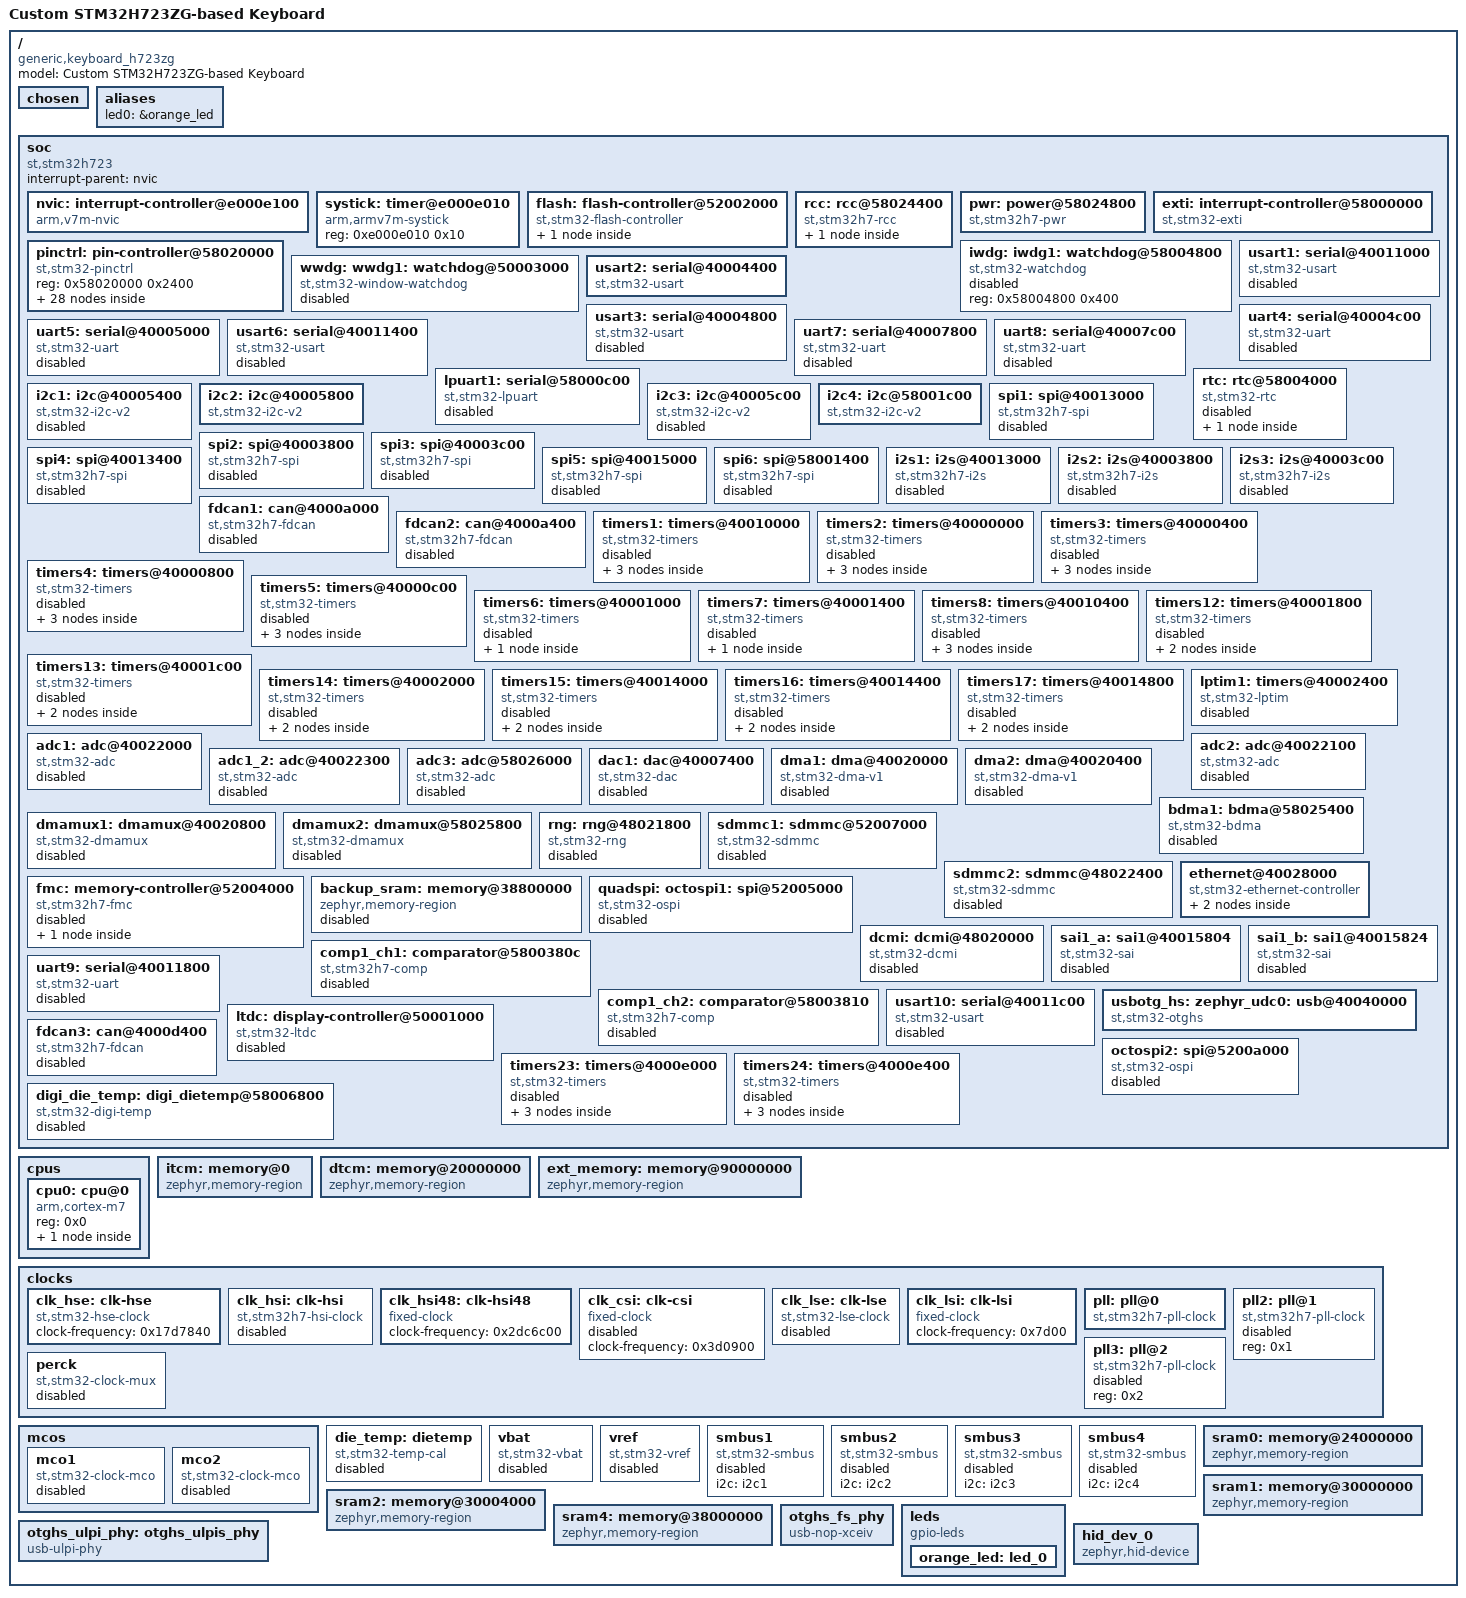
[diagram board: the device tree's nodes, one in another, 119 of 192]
/dts-v1/;

/* node '/' defined in zephyr/dts/common/skeleton.dtsi:9 */
/ {
	#address-cells = < 0x1 >;                    /* in zephyr/dts/common/skeleton.dtsi:10 */
	#size-cells = < 0x1 >;                       /* in zephyr/dts/common/skeleton.dtsi:11 */
	model = "Custom STM32H723ZG-based Keyboard"; /* in workspace/hid-keyboard/boards/generic/keyboard_h723zg/keyboard_h723zg.dts:12 */
	compatible = "generic,keyboard_h723zg";      /* in workspace/hid-keyboard/boards/generic/keyboard_h723zg/keyboard_h723zg.dts:13 */

	/* node '/chosen' defined in zephyr/dts/common/skeleton.dtsi:13 */
	chosen {
		zephyr,entropy = &rng;            /* in zephyr/dts/arm/st/h7/stm32h7.dtsi:29 */
		zephyr,flash-controller = &flash; /* in zephyr/dts/arm/st/h7/stm32h7.dtsi:30 */
		zephyr,console = &usart2;         /* in workspace/hid-keyboard/boards/generic/keyboard_h723zg/keyboard_h723zg.dts:16 */
		zephyr,shell-uart = &usart2;      /* in workspace/hid-keyboard/boards/generic/keyboard_h723zg/keyboard_h723zg.dts:17 */
		zephyr,sram = &sram0;             /* in workspace/hid-keyboard/boards/generic/keyboard_h723zg/keyboard_h723zg.dts:18 */
		zephyr,flash = &flash0;           /* in workspace/hid-keyboard/boards/generic/keyboard_h723zg/keyboard_h723zg.dts:19 */
		zephyr,dtcm = &dtcm;              /* in workspace/hid-keyboard/boards/generic/keyboard_h723zg/keyboard_h723zg.dts:20 */
	};

	/* node '/aliases' defined in zephyr/dts/common/skeleton.dtsi:15 */
	aliases {
		led0 = &orange_led; /* in workspace/hid-keyboard/boards/generic/keyboard_h723zg/keyboard_h723zg.dts:38 */
	};

	/* node '/soc' defined in zephyr/dts/arm/armv7-m.dtsi:6 */
	soc {
		#address-cells = < 0x1 >;     /* in zephyr/dts/arm/armv7-m.dtsi:7 */
		#size-cells = < 0x1 >;        /* in zephyr/dts/arm/armv7-m.dtsi:8 */
		interrupt-parent = < &nvic >; /* in zephyr/dts/arm/armv7-m.dtsi:10 */
		ranges;                       /* in zephyr/dts/arm/armv7-m.dtsi:11 */
		compatible = "st,stm32h723",
		             "st,stm32h7",
		             "simple-bus";    /* in zephyr/dts/arm/st/h7/stm32h723.dtsi:15 */

		/* node '/soc/interrupt-controller@e000e100' defined in zephyr/dts/arm/armv7-m.dtsi:13 */
		nvic: interrupt-controller@e000e100 {
			#address-cells = < 0x1 >;            /* in zephyr/dts/arm/armv7-m.dtsi:14 */
			compatible = "arm,v7m-nvic";         /* in zephyr/dts/arm/armv7-m.dtsi:15 */
			reg = < 0xe000e100 0xc00 >;          /* in zephyr/dts/arm/armv7-m.dtsi:16 */
			interrupt-controller;                /* in zephyr/dts/arm/armv7-m.dtsi:17 */
			#interrupt-cells = < 0x2 >;          /* in zephyr/dts/arm/armv7-m.dtsi:18 */
			arm,num-irq-priority-bits = < 0x4 >; /* in zephyr/dts/arm/st/h7/stm32h7.dtsi:1293 */
			phandle = < 0x1 >;                   /* in zephyr/dts/arm/armv7-m.dtsi:10 */
		};

		/* node '/soc/timer@e000e010' defined in zephyr/dts/arm/armv7-m.dtsi:21 */
		systick: timer@e000e010 {
			compatible = "arm,armv7m-systick"; /* in zephyr/dts/arm/armv7-m.dtsi:22 */
			reg = < 0xe000e010 0x10 >;         /* in zephyr/dts/arm/armv7-m.dtsi:23 */
		};

		/* node '/soc/flash-controller@52002000' defined in zephyr/dts/arm/st/h7/stm32h7.dtsi:158 */
		flash: flash-controller@52002000 {
			compatible = "st,stm32-flash-controller",
			             "st,stm32h7-flash-controller"; /* in zephyr/dts/arm/st/h7/stm32h7.dtsi:159 */
			reg = < 0x52002000 0x400 >;                 /* in zephyr/dts/arm/st/h7/stm32h7.dtsi:160 */
			interrupts = < 0x4 0x0 >;                   /* in zephyr/dts/arm/st/h7/stm32h7.dtsi:161 */
			#address-cells = < 0x1 >;                   /* in zephyr/dts/arm/st/h7/stm32h7.dtsi:163 */
			#size-cells = < 0x1 >;                      /* in zephyr/dts/arm/st/h7/stm32h7.dtsi:164 */

			/* node '/soc/flash-controller@52002000/flash@8000000' defined in zephyr/dts/arm/st/h7/stm32h723.dtsi:18 */
			flash0: flash@8000000 {
				compatible = "st,stm32-nv-flash",
				             "soc-nv-flash";      /* in zephyr/dts/arm/st/h7/stm32h723.dtsi:19 */
				write-block-size = < 0x20 >;      /* in zephyr/dts/arm/st/h7/stm32h723.dtsi:20 */
				erase-block-size = < 0x20000 >;   /* in zephyr/dts/arm/st/h7/stm32h723.dtsi:21 */
				max-erase-time = < 0xfa0 >;       /* in zephyr/dts/arm/st/h7/stm32h723.dtsi:23 */
				reg = < 0x8000000 0x100000 >;     /* in zephyr/dts/arm/st/h7/stm32h723Xg.dtsi:13 */
			};
		};

		/* node '/soc/rcc@58024400' defined in zephyr/dts/arm/st/h7/stm32h7.dtsi:167 */
		rcc: rcc@58024400 {
			compatible = "st,stm32h7-rcc";    /* in zephyr/dts/arm/st/h7/stm32h7.dtsi:168 */
			#clock-cells = < 0x2 >;           /* in zephyr/dts/arm/st/h7/stm32h7.dtsi:169 */
			reg = < 0x58024400 0x400 >;       /* in zephyr/dts/arm/st/h7/stm32h7.dtsi:170 */
			clocks = < &pll >;                /* in workspace/hid-keyboard/boards/generic/keyboard_h723zg/keyboard_h723zg.dts:66 */
			clock-frequency = < 0x20c85580 >; /* in workspace/hid-keyboard/boards/generic/keyboard_h723zg/keyboard_h723zg.dts:67 */
			d1cpre = < 0x1 >;                 /* in workspace/hid-keyboard/boards/generic/keyboard_h723zg/keyboard_h723zg.dts:68 */
			hpre = < 0x2 >;                   /* in workspace/hid-keyboard/boards/generic/keyboard_h723zg/keyboard_h723zg.dts:69 */
			d1ppre = < 0x2 >;                 /* in workspace/hid-keyboard/boards/generic/keyboard_h723zg/keyboard_h723zg.dts:70 */
			d2ppre1 = < 0x2 >;                /* in workspace/hid-keyboard/boards/generic/keyboard_h723zg/keyboard_h723zg.dts:71 */
			d2ppre2 = < 0x2 >;                /* in workspace/hid-keyboard/boards/generic/keyboard_h723zg/keyboard_h723zg.dts:72 */
			d3ppre = < 0x2 >;                 /* in workspace/hid-keyboard/boards/generic/keyboard_h723zg/keyboard_h723zg.dts:73 */
			phandle = < 0x3 >;                /* in zephyr/dts/arm/st/h7/stm32h7.dtsi:193 */

			/* node '/soc/rcc@58024400/reset-controller' defined in zephyr/dts/arm/st/h7/stm32h7.dtsi:172 */
			rctl: reset-controller {
				compatible = "st,stm32-rcc-rctl"; /* in zephyr/dts/arm/st/h7/stm32h7.dtsi:173 */
				#reset-cells = < 0x1 >;           /* in zephyr/dts/arm/st/h7/stm32h7.dtsi:174 */
				phandle = < 0x4 >;                /* in zephyr/dts/arm/st/h7/stm32h7.dtsi:316 */
			};
		};

		/* node '/soc/power@58024800' defined in zephyr/dts/arm/st/h7/stm32h7.dtsi:178 */
		pwr: power@58024800 {
			compatible = "st,stm32h7-pwr"; /* in zephyr/dts/arm/st/h7/stm32h7.dtsi:183 */
			reg = < 0x58024800 0x400 >;    /* in zephyr/dts/arm/st/h7/stm32h7.dtsi:184 */
			power-supply = "ldo";          /* in workspace/hid-keyboard/boards/generic/keyboard_h723zg/keyboard_h723zg.dts:77 */
		};

		/* node '/soc/interrupt-controller@58000000' defined in zephyr/dts/arm/st/h7/stm32h7.dtsi:187 */
		exti: interrupt-controller@58000000 {
			compatible = "st,stm32-exti";  /* in zephyr/dts/arm/st/h7/stm32h7.dtsi:188 */
			interrupt-controller;          /* in zephyr/dts/arm/st/h7/stm32h7.dtsi:189 */
			#interrupt-cells = < 0x1 >;    /* in zephyr/dts/arm/st/h7/stm32h7.dtsi:190 */
			#address-cells = < 0x0 >;      /* in zephyr/dts/arm/st/h7/stm32h7.dtsi:191 */
			reg = < 0x58000000 0x400 >;    /* in zephyr/dts/arm/st/h7/stm32h7.dtsi:192 */
			clocks = < &rcc 0xf4 0x2 >;    /* in zephyr/dts/arm/st/h7/stm32h7.dtsi:193 */
			num-lines = < 0x60 >;          /* in zephyr/dts/arm/st/h7/stm32h7.dtsi:194 */
			interrupts = < 0x6 0x0 >,
			             < 0x7 0x0 >,
			             < 0x8 0x0 >,
			             < 0x9 0x0 >,
			             < 0xa 0x0 >,
			             < 0x17 0x0 >,
			             < 0x28 0x0 >;     /* in zephyr/dts/arm/st/h7/stm32h7.dtsi:195 */
			interrupt-names = "line0",
			                  "line1",
			                  "line2",
			                  "line3",
			                  "line4",
			                  "line5-9",
			                  "line10-15"; /* in zephyr/dts/arm/st/h7/stm32h7.dtsi:197 */
			line-ranges = < 0x0 0x1 >,
			              < 0x1 0x1 >,
			              < 0x2 0x1 >,
			              < 0x3 0x1 >,
			              < 0x4 0x1 >,
			              < 0x5 0x5 >,
			              < 0xa 0x6 >;     /* in zephyr/dts/arm/st/h7/stm32h7.dtsi:199 */
		};

		/* node '/soc/pin-controller@58020000' defined in zephyr/dts/arm/st/h7/stm32h7.dtsi:203 */
		pinctrl: pin-controller@58020000 {
			compatible = "st,stm32-pinctrl"; /* in zephyr/dts/arm/st/h7/stm32h7.dtsi:204 */
			#address-cells = < 0x1 >;        /* in zephyr/dts/arm/st/h7/stm32h7.dtsi:205 */
			#size-cells = < 0x1 >;           /* in zephyr/dts/arm/st/h7/stm32h7.dtsi:206 */
			reg = < 0x58020000 0x2400 >;     /* in zephyr/dts/arm/st/h7/stm32h7.dtsi:207 */

			/* node '/soc/pin-controller@58020000/gpio@58020000' defined in zephyr/dts/arm/st/h7/stm32h7.dtsi:209 */
			gpioa: gpio@58020000 {
				compatible = "st,stm32-gpio"; /* in zephyr/dts/arm/st/h7/stm32h7.dtsi:210 */
				gpio-controller;              /* in zephyr/dts/arm/st/h7/stm32h7.dtsi:211 */
				#gpio-cells = < 0x2 >;        /* in zephyr/dts/arm/st/h7/stm32h7.dtsi:212 */
				reg = < 0x58020000 0x400 >;   /* in zephyr/dts/arm/st/h7/stm32h7.dtsi:213 */
				clocks = < &rcc 0xe0 0x1 >;   /* in zephyr/dts/arm/st/h7/stm32h7.dtsi:214 */
			};

			/* node '/soc/pin-controller@58020000/gpio@58020400' defined in zephyr/dts/arm/st/h7/stm32h7.dtsi:217 */
			gpiob: gpio@58020400 {
				compatible = "st,stm32-gpio"; /* in zephyr/dts/arm/st/h7/stm32h7.dtsi:218 */
				gpio-controller;              /* in zephyr/dts/arm/st/h7/stm32h7.dtsi:219 */
				#gpio-cells = < 0x2 >;        /* in zephyr/dts/arm/st/h7/stm32h7.dtsi:220 */
				reg = < 0x58020400 0x400 >;   /* in zephyr/dts/arm/st/h7/stm32h7.dtsi:221 */
				clocks = < &rcc 0xe0 0x2 >;   /* in zephyr/dts/arm/st/h7/stm32h7.dtsi:222 */
			};

			/* node '/soc/pin-controller@58020000/gpio@58020800' defined in zephyr/dts/arm/st/h7/stm32h7.dtsi:225 */
			gpioc: gpio@58020800 {
				compatible = "st,stm32-gpio"; /* in zephyr/dts/arm/st/h7/stm32h7.dtsi:226 */
				gpio-controller;              /* in zephyr/dts/arm/st/h7/stm32h7.dtsi:227 */
				#gpio-cells = < 0x2 >;        /* in zephyr/dts/arm/st/h7/stm32h7.dtsi:228 */
				reg = < 0x58020800 0x400 >;   /* in zephyr/dts/arm/st/h7/stm32h7.dtsi:229 */
				clocks = < &rcc 0xe0 0x4 >;   /* in zephyr/dts/arm/st/h7/stm32h7.dtsi:230 */
			};

			/* node '/soc/pin-controller@58020000/gpio@58020c00' defined in zephyr/dts/arm/st/h7/stm32h7.dtsi:233 */
			gpiod: gpio@58020c00 {
				compatible = "st,stm32-gpio"; /* in zephyr/dts/arm/st/h7/stm32h7.dtsi:234 */
				gpio-controller;              /* in zephyr/dts/arm/st/h7/stm32h7.dtsi:235 */
				#gpio-cells = < 0x2 >;        /* in zephyr/dts/arm/st/h7/stm32h7.dtsi:236 */
				reg = < 0x58020c00 0x400 >;   /* in zephyr/dts/arm/st/h7/stm32h7.dtsi:237 */
				clocks = < &rcc 0xe0 0x8 >;   /* in zephyr/dts/arm/st/h7/stm32h7.dtsi:238 */
				phandle = < 0x20 >;           /* in workspace/hid-keyboard/boards/generic/keyboard_h723zg/keyboard_h723zg.dts:27 */
			};

			/* node '/soc/pin-controller@58020000/gpio@58021000' defined in zephyr/dts/arm/st/h7/stm32h7.dtsi:241 */
			gpioe: gpio@58021000 {
				compatible = "st,stm32-gpio"; /* in zephyr/dts/arm/st/h7/stm32h7.dtsi:242 */
				gpio-controller;              /* in zephyr/dts/arm/st/h7/stm32h7.dtsi:243 */
				#gpio-cells = < 0x2 >;        /* in zephyr/dts/arm/st/h7/stm32h7.dtsi:244 */
				reg = < 0x58021000 0x400 >;   /* in zephyr/dts/arm/st/h7/stm32h7.dtsi:245 */
				clocks = < &rcc 0xe0 0x10 >;  /* in zephyr/dts/arm/st/h7/stm32h7.dtsi:246 */
			};

			/* node '/soc/pin-controller@58020000/gpio@58021400' defined in zephyr/dts/arm/st/h7/stm32h7.dtsi:249 */
			gpiof: gpio@58021400 {
				compatible = "st,stm32-gpio"; /* in zephyr/dts/arm/st/h7/stm32h7.dtsi:250 */
				gpio-controller;              /* in zephyr/dts/arm/st/h7/stm32h7.dtsi:251 */
				#gpio-cells = < 0x2 >;        /* in zephyr/dts/arm/st/h7/stm32h7.dtsi:252 */
				reg = < 0x58021400 0x400 >;   /* in zephyr/dts/arm/st/h7/stm32h7.dtsi:253 */
				clocks = < &rcc 0xe0 0x20 >;  /* in zephyr/dts/arm/st/h7/stm32h7.dtsi:254 */
			};

			/* node '/soc/pin-controller@58020000/gpio@58021800' defined in zephyr/dts/arm/st/h7/stm32h7.dtsi:257 */
			gpiog: gpio@58021800 {
				compatible = "st,stm32-gpio"; /* in zephyr/dts/arm/st/h7/stm32h7.dtsi:258 */
				gpio-controller;              /* in zephyr/dts/arm/st/h7/stm32h7.dtsi:259 */
				#gpio-cells = < 0x2 >;        /* in zephyr/dts/arm/st/h7/stm32h7.dtsi:260 */
				reg = < 0x58021800 0x400 >;   /* in zephyr/dts/arm/st/h7/stm32h7.dtsi:261 */
				clocks = < &rcc 0xe0 0x40 >;  /* in zephyr/dts/arm/st/h7/stm32h7.dtsi:262 */
			};

			/* node '/soc/pin-controller@58020000/gpio@58021c00' defined in zephyr/dts/arm/st/h7/stm32h7.dtsi:265 */
			gpioh: gpio@58021c00 {
				compatible = "st,stm32-gpio"; /* in zephyr/dts/arm/st/h7/stm32h7.dtsi:266 */
				gpio-controller;              /* in zephyr/dts/arm/st/h7/stm32h7.dtsi:267 */
				#gpio-cells = < 0x2 >;        /* in zephyr/dts/arm/st/h7/stm32h7.dtsi:268 */
				reg = < 0x58021c00 0x400 >;   /* in zephyr/dts/arm/st/h7/stm32h7.dtsi:269 */
				clocks = < &rcc 0xe0 0x80 >;  /* in zephyr/dts/arm/st/h7/stm32h7.dtsi:270 */
			};

			/* node '/soc/pin-controller@58020000/gpio@58022000' defined in zephyr/dts/arm/st/h7/stm32h7.dtsi:273 */
			gpioi: gpio@58022000 {
				compatible = "st,stm32-gpio"; /* in zephyr/dts/arm/st/h7/stm32h7.dtsi:274 */
				gpio-controller;              /* in zephyr/dts/arm/st/h7/stm32h7.dtsi:275 */
				#gpio-cells = < 0x2 >;        /* in zephyr/dts/arm/st/h7/stm32h7.dtsi:276 */
				reg = < 0x58022000 0x400 >;   /* in zephyr/dts/arm/st/h7/stm32h7.dtsi:277 */
				clocks = < &rcc 0xe0 0x100 >; /* in zephyr/dts/arm/st/h7/stm32h7.dtsi:278 */
			};

			/* node '/soc/pin-controller@58020000/gpio@58022400' defined in zephyr/dts/arm/st/h7/stm32h7.dtsi:281 */
			gpioj: gpio@58022400 {
				compatible = "st,stm32-gpio"; /* in zephyr/dts/arm/st/h7/stm32h7.dtsi:282 */
				gpio-controller;              /* in zephyr/dts/arm/st/h7/stm32h7.dtsi:283 */
				#gpio-cells = < 0x2 >;        /* in zephyr/dts/arm/st/h7/stm32h7.dtsi:284 */
				reg = < 0x58022400 0x400 >;   /* in zephyr/dts/arm/st/h7/stm32h7.dtsi:285 */
				clocks = < &rcc 0xe0 0x200 >; /* in zephyr/dts/arm/st/h7/stm32h7.dtsi:286 */
			};

			/* node '/soc/pin-controller@58020000/gpio@58022800' defined in zephyr/dts/arm/st/h7/stm32h7.dtsi:289 */
			gpiok: gpio@58022800 {
				compatible = "st,stm32-gpio"; /* in zephyr/dts/arm/st/h7/stm32h7.dtsi:290 */
				gpio-controller;              /* in zephyr/dts/arm/st/h7/stm32h7.dtsi:291 */
				#gpio-cells = < 0x2 >;        /* in zephyr/dts/arm/st/h7/stm32h7.dtsi:292 */
				reg = < 0x58022800 0x400 >;   /* in zephyr/dts/arm/st/h7/stm32h7.dtsi:293 */
				clocks = < &rcc 0xe0 0x400 >; /* in zephyr/dts/arm/st/h7/stm32h7.dtsi:294 */
			};

			/* node '/soc/pin-controller@58020000/i2c2_scl_pf1' defined in modules/hal/stm32/dts/st/h7/stm32h723zgtx-pinctrl.dtsi:1919 */
			i2c2_scl_pf1: i2c2_scl_pf1 {
				pinmux = < 0xa24 >; /* in modules/hal/stm32/dts/st/h7/stm32h723zgtx-pinctrl.dtsi:1920 */
				bias-pull-up;       /* in modules/hal/stm32/dts/st/h7/stm32h723zgtx-pinctrl.dtsi:1921 */
				drive-open-drain;   /* in modules/hal/stm32/dts/st/h7/stm32h723zgtx-pinctrl.dtsi:1922 */
				phandle = < 0x6 >;  /* in workspace/hid-keyboard/boards/generic/keyboard_h723zg/keyboard_h723zg.dts:99 */
			};

			/* node '/soc/pin-controller@58020000/i2c4_scl_pf14' defined in modules/hal/stm32/dts/st/h7/stm32h723zgtx-pinctrl.dtsi:1949 */
			i2c4_scl_pf14: i2c4_scl_pf14 {
				pinmux = < 0xbc4 >; /* in modules/hal/stm32/dts/st/h7/stm32h723zgtx-pinctrl.dtsi:1950 */
				bias-pull-up;       /* in modules/hal/stm32/dts/st/h7/stm32h723zgtx-pinctrl.dtsi:1951 */
				drive-open-drain;   /* in modules/hal/stm32/dts/st/h7/stm32h723zgtx-pinctrl.dtsi:1952 */
				phandle = < 0x8 >;  /* in workspace/hid-keyboard/boards/generic/keyboard_h723zg/keyboard_h723zg.dts:92 */
			};

			/* node '/soc/pin-controller@58020000/i2c2_sda_pf0' defined in modules/hal/stm32/dts/st/h7/stm32h723zgtx-pinctrl.dtsi:1993 */
			i2c2_sda_pf0: i2c2_sda_pf0 {
				pinmux = < 0xa04 >; /* in modules/hal/stm32/dts/st/h7/stm32h723zgtx-pinctrl.dtsi:1994 */
				bias-pull-up;       /* in modules/hal/stm32/dts/st/h7/stm32h723zgtx-pinctrl.dtsi:1995 */
				drive-open-drain;   /* in modules/hal/stm32/dts/st/h7/stm32h723zgtx-pinctrl.dtsi:1996 */
				phandle = < 0x7 >;  /* in workspace/hid-keyboard/boards/generic/keyboard_h723zg/keyboard_h723zg.dts:99 */
			};

			/* node '/soc/pin-controller@58020000/i2c4_sda_pf15' defined in modules/hal/stm32/dts/st/h7/stm32h723zgtx-pinctrl.dtsi:2023 */
			i2c4_sda_pf15: i2c4_sda_pf15 {
				pinmux = < 0xbe4 >; /* in modules/hal/stm32/dts/st/h7/stm32h723zgtx-pinctrl.dtsi:2024 */
				bias-pull-up;       /* in modules/hal/stm32/dts/st/h7/stm32h723zgtx-pinctrl.dtsi:2025 */
				drive-open-drain;   /* in modules/hal/stm32/dts/st/h7/stm32h723zgtx-pinctrl.dtsi:2026 */
				phandle = < 0x9 >;  /* in workspace/hid-keyboard/boards/generic/keyboard_h723zg/keyboard_h723zg.dts:92 */
			};

			/* node '/soc/pin-controller@58020000/usart2_tx_pa2' defined in modules/hal/stm32/dts/st/h7/stm32h723zgtx-pinctrl.dtsi:4608 */
			usart2_tx_pa2: usart2_tx_pa2 {
				pinmux = < 0x47 >; /* in modules/hal/stm32/dts/st/h7/stm32h723zgtx-pinctrl.dtsi:4609 */
				bias-pull-up;      /* in modules/hal/stm32/dts/st/h7/stm32h723zgtx-pinctrl.dtsi:4610 */
				phandle = < 0x5 >; /* in workspace/hid-keyboard/boards/generic/keyboard_h723zg/keyboard_h723zg.dts:81 */
			};

			/* node '/soc/pin-controller@58020000/usb_otg_hs_ulpi_d0_pa3' defined in modules/hal/stm32/dts/st/h7/stm32h723zgtx-pinctrl.dtsi:4742 */
			usb_otg_hs_ulpi_d0_pa3: usb_otg_hs_ulpi_d0_pa3 {
				pinmux = < 0x6a >;        /* in modules/hal/stm32/dts/st/h7/stm32h723zgtx-pinctrl.dtsi:4743 */
				slew-rate = "high-speed"; /* in modules/hal/stm32/dts/st/h7/stm32h723zgtx-pinctrl.dtsi:4744 */
				phandle = < 0xe >;        /* in workspace/hid-keyboard/boards/generic/keyboard_h723zg/keyboard_h723zg.dts:107 */
			};

			/* node '/soc/pin-controller@58020000/usb_otg_hs_ulpi_ck_pa5' defined in modules/hal/stm32/dts/st/h7/stm32h723zgtx-pinctrl.dtsi:4747 */
			usb_otg_hs_ulpi_ck_pa5: usb_otg_hs_ulpi_ck_pa5 {
				pinmux = < 0xaa >;        /* in modules/hal/stm32/dts/st/h7/stm32h723zgtx-pinctrl.dtsi:4748 */
				slew-rate = "high-speed"; /* in modules/hal/stm32/dts/st/h7/stm32h723zgtx-pinctrl.dtsi:4749 */
				phandle = < 0xd >;        /* in workspace/hid-keyboard/boards/generic/keyboard_h723zg/keyboard_h723zg.dts:107 */
			};

			/* node '/soc/pin-controller@58020000/usb_otg_hs_ulpi_d1_pb0' defined in modules/hal/stm32/dts/st/h7/stm32h723zgtx-pinctrl.dtsi:4752 */
			usb_otg_hs_ulpi_d1_pb0: usb_otg_hs_ulpi_d1_pb0 {
				pinmux = < 0x20a >;       /* in modules/hal/stm32/dts/st/h7/stm32h723zgtx-pinctrl.dtsi:4753 */
				slew-rate = "high-speed"; /* in modules/hal/stm32/dts/st/h7/stm32h723zgtx-pinctrl.dtsi:4754 */
				phandle = < 0xf >;        /* in workspace/hid-keyboard/boards/generic/keyboard_h723zg/keyboard_h723zg.dts:107 */
			};

			/* node '/soc/pin-controller@58020000/usb_otg_hs_ulpi_d2_pb1' defined in modules/hal/stm32/dts/st/h7/stm32h723zgtx-pinctrl.dtsi:4757 */
			usb_otg_hs_ulpi_d2_pb1: usb_otg_hs_ulpi_d2_pb1 {
				pinmux = < 0x22a >;       /* in modules/hal/stm32/dts/st/h7/stm32h723zgtx-pinctrl.dtsi:4758 */
				slew-rate = "high-speed"; /* in modules/hal/stm32/dts/st/h7/stm32h723zgtx-pinctrl.dtsi:4759 */
				phandle = < 0x10 >;       /* in workspace/hid-keyboard/boards/generic/keyboard_h723zg/keyboard_h723zg.dts:107 */
			};

			/* node '/soc/pin-controller@58020000/usb_otg_hs_ulpi_d7_pb5' defined in modules/hal/stm32/dts/st/h7/stm32h723zgtx-pinctrl.dtsi:4762 */
			usb_otg_hs_ulpi_d7_pb5: usb_otg_hs_ulpi_d7_pb5 {
				pinmux = < 0x2aa >;       /* in modules/hal/stm32/dts/st/h7/stm32h723zgtx-pinctrl.dtsi:4763 */
				slew-rate = "high-speed"; /* in modules/hal/stm32/dts/st/h7/stm32h723zgtx-pinctrl.dtsi:4764 */
				phandle = < 0x15 >;       /* in workspace/hid-keyboard/boards/generic/keyboard_h723zg/keyboard_h723zg.dts:107 */
			};

			/* node '/soc/pin-controller@58020000/usb_otg_hs_ulpi_d3_pb10' defined in modules/hal/stm32/dts/st/h7/stm32h723zgtx-pinctrl.dtsi:4767 */
			usb_otg_hs_ulpi_d3_pb10: usb_otg_hs_ulpi_d3_pb10 {
				pinmux = < 0x34a >;       /* in modules/hal/stm32/dts/st/h7/stm32h723zgtx-pinctrl.dtsi:4768 */
				slew-rate = "high-speed"; /* in modules/hal/stm32/dts/st/h7/stm32h723zgtx-pinctrl.dtsi:4769 */
				phandle = < 0x11 >;       /* in workspace/hid-keyboard/boards/generic/keyboard_h723zg/keyboard_h723zg.dts:107 */
			};

			/* node '/soc/pin-controller@58020000/usb_otg_hs_ulpi_d4_pb11' defined in modules/hal/stm32/dts/st/h7/stm32h723zgtx-pinctrl.dtsi:4772 */
			usb_otg_hs_ulpi_d4_pb11: usb_otg_hs_ulpi_d4_pb11 {
				pinmux = < 0x36a >;       /* in modules/hal/stm32/dts/st/h7/stm32h723zgtx-pinctrl.dtsi:4773 */
				slew-rate = "high-speed"; /* in modules/hal/stm32/dts/st/h7/stm32h723zgtx-pinctrl.dtsi:4774 */
				phandle = < 0x12 >;       /* in workspace/hid-keyboard/boards/generic/keyboard_h723zg/keyboard_h723zg.dts:107 */
			};

			/* node '/soc/pin-controller@58020000/usb_otg_hs_ulpi_d5_pb12' defined in modules/hal/stm32/dts/st/h7/stm32h723zgtx-pinctrl.dtsi:4777 */
			usb_otg_hs_ulpi_d5_pb12: usb_otg_hs_ulpi_d5_pb12 {
				pinmux = < 0x38a >;       /* in modules/hal/stm32/dts/st/h7/stm32h723zgtx-pinctrl.dtsi:4778 */
				slew-rate = "high-speed"; /* in modules/hal/stm32/dts/st/h7/stm32h723zgtx-pinctrl.dtsi:4779 */
				phandle = < 0x13 >;       /* in workspace/hid-keyboard/boards/generic/keyboard_h723zg/keyboard_h723zg.dts:107 */
			};

			/* node '/soc/pin-controller@58020000/usb_otg_hs_ulpi_d6_pb13' defined in modules/hal/stm32/dts/st/h7/stm32h723zgtx-pinctrl.dtsi:4782 */
			usb_otg_hs_ulpi_d6_pb13: usb_otg_hs_ulpi_d6_pb13 {
				pinmux = < 0x3aa >;       /* in modules/hal/stm32/dts/st/h7/stm32h723zgtx-pinctrl.dtsi:4783 */
				slew-rate = "high-speed"; /* in modules/hal/stm32/dts/st/h7/stm32h723zgtx-pinctrl.dtsi:4784 */
				phandle = < 0x14 >;       /* in workspace/hid-keyboard/boards/generic/keyboard_h723zg/keyboard_h723zg.dts:107 */
			};

			/* node '/soc/pin-controller@58020000/usb_otg_hs_ulpi_stp_pc0' defined in modules/hal/stm32/dts/st/h7/stm32h723zgtx-pinctrl.dtsi:4787 */
			usb_otg_hs_ulpi_stp_pc0: usb_otg_hs_ulpi_stp_pc0 {
				pinmux = < 0x40a >;       /* in modules/hal/stm32/dts/st/h7/stm32h723zgtx-pinctrl.dtsi:4788 */
				slew-rate = "high-speed"; /* in modules/hal/stm32/dts/st/h7/stm32h723zgtx-pinctrl.dtsi:4789 */
				phandle = < 0x16 >;       /* in workspace/hid-keyboard/boards/generic/keyboard_h723zg/keyboard_h723zg.dts:107 */
			};

			/* node '/soc/pin-controller@58020000/usb_otg_hs_ulpi_dir_pc2_c' defined in modules/hal/stm32/dts/st/h7/stm32h723zgtx-pinctrl.dtsi:4792 */
			usb_otg_hs_ulpi_dir_pc2_c: usb_otg_hs_ulpi_dir_pc2_c {
				pinmux = < 0x44a >;       /* in modules/hal/stm32/dts/st/h7/stm32h723zgtx-pinctrl.dtsi:4793 */
				slew-rate = "high-speed"; /* in modules/hal/stm32/dts/st/h7/stm32h723zgtx-pinctrl.dtsi:4794 */
				phandle = < 0x17 >;       /* in workspace/hid-keyboard/boards/generic/keyboard_h723zg/keyboard_h723zg.dts:107 */
			};

			/* node '/soc/pin-controller@58020000/usb_otg_hs_ulpi_nxt_pc3_c' defined in modules/hal/stm32/dts/st/h7/stm32h723zgtx-pinctrl.dtsi:4797 */
			usb_otg_hs_ulpi_nxt_pc3_c: usb_otg_hs_ulpi_nxt_pc3_c {
				pinmux = < 0x46a >;       /* in modules/hal/stm32/dts/st/h7/stm32h723zgtx-pinctrl.dtsi:4798 */
				slew-rate = "high-speed"; /* in modules/hal/stm32/dts/st/h7/stm32h723zgtx-pinctrl.dtsi:4799 */
				phandle = < 0x18 >;       /* in workspace/hid-keyboard/boards/generic/keyboard_h723zg/keyboard_h723zg.dts:107 */
			};
		};

		/* node '/soc/watchdog@58004800' defined in zephyr/dts/arm/st/h7/stm32h7.dtsi:298 */
		iwdg: iwdg1: watchdog@58004800 {
			compatible = "st,stm32-watchdog"; /* in zephyr/dts/arm/st/h7/stm32h7.dtsi:299 */
			reg = < 0x58004800 0x400 >;       /* in zephyr/dts/arm/st/h7/stm32h7.dtsi:300 */
			status = "disabled";              /* in zephyr/dts/arm/st/h7/stm32h7.dtsi:301 */
		};

		/* node '/soc/watchdog@50003000' defined in zephyr/dts/arm/st/h7/stm32h7.dtsi:304 */
		wwdg: wwdg1: watchdog@50003000 {
			compatible = "st,stm32-window-watchdog"; /* in zephyr/dts/arm/st/h7/stm32h7.dtsi:305 */
			reg = < 0x50003000 0x1000 >;             /* in zephyr/dts/arm/st/h7/stm32h7.dtsi:306 */
			clocks = < &rcc 0xe4 0x40 >;             /* in zephyr/dts/arm/st/h7/stm32h7.dtsi:307 */
			interrupts = < 0x0 0x7 >;                /* in zephyr/dts/arm/st/h7/stm32h7.dtsi:308 */
			status = "disabled";                     /* in zephyr/dts/arm/st/h7/stm32h7.dtsi:309 */
		};

		/* node '/soc/serial@40011000' defined in zephyr/dts/arm/st/h7/stm32h7.dtsi:312 */
		usart1: serial@40011000 {
			compatible = "st,stm32-usart",
			             "st,stm32-uart";  /* in zephyr/dts/arm/st/h7/stm32h7.dtsi:313 */
			reg = < 0x40011000 0x400 >;    /* in zephyr/dts/arm/st/h7/stm32h7.dtsi:314 */
			clocks = < &rcc 0xf0 0x10 >;   /* in zephyr/dts/arm/st/h7/stm32h7.dtsi:315 */
			resets = < &rctl 0x1304 >;     /* in zephyr/dts/arm/st/h7/stm32h7.dtsi:316 */
			interrupts = < 0x25 0x0 >;     /* in zephyr/dts/arm/st/h7/stm32h7.dtsi:317 */
			status = "disabled";           /* in zephyr/dts/arm/st/h7/stm32h7.dtsi:318 */
		};

		/* node '/soc/serial@40004400' defined in zephyr/dts/arm/st/h7/stm32h7.dtsi:321 */
		usart2: serial@40004400 {
			compatible = "st,stm32-usart",
			             "st,stm32-uart";   /* in zephyr/dts/arm/st/h7/stm32h7.dtsi:322 */
			reg = < 0x40004400 0x400 >;     /* in zephyr/dts/arm/st/h7/stm32h7.dtsi:323 */
			clocks = < &rcc 0xe8 0x20000 >; /* in zephyr/dts/arm/st/h7/stm32h7.dtsi:324 */
			resets = < &rctl 0x1211 >;      /* in zephyr/dts/arm/st/h7/stm32h7.dtsi:325 */
			interrupts = < 0x26 0x0 >;      /* in zephyr/dts/arm/st/h7/stm32h7.dtsi:326 */
			pinctrl-0 = < &usart2_tx_pa2 >; /* in workspace/hid-keyboard/boards/generic/keyboard_h723zg/keyboard_h723zg.dts:81 */
			pinctrl-names = "default";      /* in workspace/hid-keyboard/boards/generic/keyboard_h723zg/keyboard_h723zg.dts:82 */
			current-speed = < 0x1c200 >;    /* in workspace/hid-keyboard/boards/generic/keyboard_h723zg/keyboard_h723zg.dts:83 */
			status = "okay";                /* in workspace/hid-keyboard/boards/generic/keyboard_h723zg/keyboard_h723zg.dts:84 */
		};

		/* node '/soc/serial@40004800' defined in zephyr/dts/arm/st/h7/stm32h7.dtsi:330 */
		usart3: serial@40004800 {
			compatible = "st,stm32-usart",
			             "st,stm32-uart";   /* in zephyr/dts/arm/st/h7/stm32h7.dtsi:331 */
			reg = < 0x40004800 0x400 >;     /* in zephyr/dts/arm/st/h7/stm32h7.dtsi:332 */
			clocks = < &rcc 0xe8 0x40000 >; /* in zephyr/dts/arm/st/h7/stm32h7.dtsi:333 */
			resets = < &rctl 0x1212 >;      /* in zephyr/dts/arm/st/h7/stm32h7.dtsi:334 */
			interrupts = < 0x27 0x0 >;      /* in zephyr/dts/arm/st/h7/stm32h7.dtsi:335 */
			status = "disabled";            /* in zephyr/dts/arm/st/h7/stm32h7.dtsi:336 */
		};

		/* node '/soc/serial@40004c00' defined in zephyr/dts/arm/st/h7/stm32h7.dtsi:339 */
		uart4: serial@40004c00 {
			compatible = "st,stm32-uart";   /* in zephyr/dts/arm/st/h7/stm32h7.dtsi:340 */
			reg = < 0x40004c00 0x400 >;     /* in zephyr/dts/arm/st/h7/stm32h7.dtsi:341 */
			clocks = < &rcc 0xe8 0x80000 >; /* in zephyr/dts/arm/st/h7/stm32h7.dtsi:342 */
			resets = < &rctl 0x1213 >;      /* in zephyr/dts/arm/st/h7/stm32h7.dtsi:343 */
			interrupts = < 0x34 0x0 >;      /* in zephyr/dts/arm/st/h7/stm32h7.dtsi:344 */
			status = "disabled";            /* in zephyr/dts/arm/st/h7/stm32h7.dtsi:345 */
		};

		/* node '/soc/serial@40005000' defined in zephyr/dts/arm/st/h7/stm32h7.dtsi:348 */
		uart5: serial@40005000 {
			compatible = "st,stm32-uart";    /* in zephyr/dts/arm/st/h7/stm32h7.dtsi:349 */
			reg = < 0x40005000 0x400 >;      /* in zephyr/dts/arm/st/h7/stm32h7.dtsi:350 */
			clocks = < &rcc 0xe8 0x100000 >; /* in zephyr/dts/arm/st/h7/stm32h7.dtsi:351 */
			resets = < &rctl 0x1214 >;       /* in zephyr/dts/arm/st/h7/stm32h7.dtsi:352 */
			interrupts = < 0x35 0x0 >;       /* in zephyr/dts/arm/st/h7/stm32h7.dtsi:353 */
			status = "disabled";             /* in zephyr/dts/arm/st/h7/stm32h7.dtsi:354 */
		};

		/* node '/soc/serial@40011400' defined in zephyr/dts/arm/st/h7/stm32h7.dtsi:357 */
		usart6: serial@40011400 {
			compatible = "st,stm32-usart",
			             "st,stm32-uart";  /* in zephyr/dts/arm/st/h7/stm32h7.dtsi:358 */
			reg = < 0x40011400 0x400 >;    /* in zephyr/dts/arm/st/h7/stm32h7.dtsi:359 */
			clocks = < &rcc 0xf0 0x20 >;   /* in zephyr/dts/arm/st/h7/stm32h7.dtsi:360 */
			resets = < &rctl 0x1305 >;     /* in zephyr/dts/arm/st/h7/stm32h7.dtsi:361 */
			interrupts = < 0x47 0x0 >;     /* in zephyr/dts/arm/st/h7/stm32h7.dtsi:362 */
			status = "disabled";           /* in zephyr/dts/arm/st/h7/stm32h7.dtsi:363 */
		};

		/* node '/soc/serial@40007800' defined in zephyr/dts/arm/st/h7/stm32h7.dtsi:366 */
		uart7: serial@40007800 {
			compatible = "st,stm32-uart";      /* in zephyr/dts/arm/st/h7/stm32h7.dtsi:367 */
			reg = < 0x40007800 0x400 >;        /* in zephyr/dts/arm/st/h7/stm32h7.dtsi:368 */
			clocks = < &rcc 0xe8 0x40000000 >; /* in zephyr/dts/arm/st/h7/stm32h7.dtsi:369 */
			resets = < &rctl 0x121e >;         /* in zephyr/dts/arm/st/h7/stm32h7.dtsi:370 */
			interrupts = < 0x52 0x0 >;         /* in zephyr/dts/arm/st/h7/stm32h7.dtsi:371 */
			status = "disabled";               /* in zephyr/dts/arm/st/h7/stm32h7.dtsi:372 */
		};

		/* node '/soc/serial@40007c00' defined in zephyr/dts/arm/st/h7/stm32h7.dtsi:375 */
		uart8: serial@40007c00 {
			compatible = "st,stm32-uart";      /* in zephyr/dts/arm/st/h7/stm32h7.dtsi:376 */
			reg = < 0x40007c00 0x400 >;        /* in zephyr/dts/arm/st/h7/stm32h7.dtsi:377 */
			clocks = < &rcc 0xe8 0x80000000 >; /* in zephyr/dts/arm/st/h7/stm32h7.dtsi:378 */
			resets = < &rctl 0x121f >;         /* in zephyr/dts/arm/st/h7/stm32h7.dtsi:379 */
			interrupts = < 0x53 0x0 >;         /* in zephyr/dts/arm/st/h7/stm32h7.dtsi:380 */
			status = "disabled";               /* in zephyr/dts/arm/st/h7/stm32h7.dtsi:381 */
		};

		/* node '/soc/serial@58000c00' defined in zephyr/dts/arm/st/h7/stm32h7.dtsi:384 */
		lpuart1: serial@58000c00 {
			compatible = "st,stm32-lpuart",
			             "st,stm32-uart";   /* in zephyr/dts/arm/st/h7/stm32h7.dtsi:385 */
			reg = < 0x58000c00 0x400 >;     /* in zephyr/dts/arm/st/h7/stm32h7.dtsi:386 */
			clocks = < &rcc 0xf4 0x8 >;     /* in zephyr/dts/arm/st/h7/stm32h7.dtsi:387 */
			resets = < &rctl 0x1383 >;      /* in zephyr/dts/arm/st/h7/stm32h7.dtsi:388 */
			interrupts = < 0x8e 0x0 >;      /* in zephyr/dts/arm/st/h7/stm32h7.dtsi:389 */
			status = "disabled";            /* in zephyr/dts/arm/st/h7/stm32h7.dtsi:390 */
		};

		/* node '/soc/rtc@58004000' defined in zephyr/dts/arm/st/h7/stm32h7.dtsi:393 */
		rtc: rtc@58004000 {
			compatible = "st,stm32-rtc";    /* in zephyr/dts/arm/st/h7/stm32h7.dtsi:394 */
			reg = < 0x58004000 0x400 >;     /* in zephyr/dts/arm/st/h7/stm32h7.dtsi:395 */
			interrupts = < 0x29 0x0 >;      /* in zephyr/dts/arm/st/h7/stm32h7.dtsi:396 */
			clocks = < &rcc 0xf4 0x10000 >; /* in zephyr/dts/arm/st/h7/stm32h7.dtsi:397 */
			prescaler = < 0x8000 >;         /* in zephyr/dts/arm/st/h7/stm32h7.dtsi:398 */
			alarms-count = < 0x2 >;         /* in zephyr/dts/arm/st/h7/stm32h7.dtsi:399 */
			alrm-exti-line = < 0x11 >;      /* in zephyr/dts/arm/st/h7/stm32h7.dtsi:400 */
			status = "disabled";            /* in workspace/hid-keyboard/boards/generic/keyboard_h723zg/keyboard_h723zg.dts:88 */

			/* node '/soc/rtc@58004000/backup_regs' defined in zephyr/dts/arm/st/h7/stm32h723.dtsi:130 */
			bbram: backup_regs {
				compatible = "st,stm32-bbram"; /* in zephyr/dts/arm/st/h7/stm32h723.dtsi:131 */
				st,backup-regs = < 0x20 >;     /* in zephyr/dts/arm/st/h7/stm32h723.dtsi:132 */
				status = "disabled";           /* in zephyr/dts/arm/st/h7/stm32h723.dtsi:133 */
			};
		};

		/* node '/soc/i2c@40005400' defined in zephyr/dts/arm/st/h7/stm32h7.dtsi:404 */
		i2c1: i2c@40005400 {
			compatible = "st,stm32-i2c-v2";  /* in zephyr/dts/arm/st/h7/stm32h7.dtsi:405 */
			clock-frequency = < 0x186a0 >;   /* in zephyr/dts/arm/st/h7/stm32h7.dtsi:406 */
			#address-cells = < 0x1 >;        /* in zephyr/dts/arm/st/h7/stm32h7.dtsi:407 */
			#size-cells = < 0x0 >;           /* in zephyr/dts/arm/st/h7/stm32h7.dtsi:408 */
			reg = < 0x40005400 0x400 >;      /* in zephyr/dts/arm/st/h7/stm32h7.dtsi:409 */
			clocks = < &rcc 0xe8 0x200000 >; /* in zephyr/dts/arm/st/h7/stm32h7.dtsi:410 */
			interrupts = < 0x1f 0x0 >,
			             < 0x20 0x0 >;       /* in zephyr/dts/arm/st/h7/stm32h7.dtsi:411 */
			interrupt-names = "event",
			                  "error";       /* in zephyr/dts/arm/st/h7/stm32h7.dtsi:412 */
			status = "disabled";             /* in zephyr/dts/arm/st/h7/stm32h7.dtsi:413 */
			phandle = < 0x1c >;              /* in zephyr/dts/arm/st/h7/stm32h7.dtsi:1263 */
		};

		/* node '/soc/i2c@40005800' defined in zephyr/dts/arm/st/h7/stm32h7.dtsi:416 */
		i2c2: i2c@40005800 {
			compatible = "st,stm32-i2c-v2";              /* in zephyr/dts/arm/st/h7/stm32h7.dtsi:417 */
			#address-cells = < 0x1 >;                    /* in zephyr/dts/arm/st/h7/stm32h7.dtsi:419 */
			#size-cells = < 0x0 >;                       /* in zephyr/dts/arm/st/h7/stm32h7.dtsi:420 */
			reg = < 0x40005800 0x400 >;                  /* in zephyr/dts/arm/st/h7/stm32h7.dtsi:421 */
			clocks = < &rcc 0xe8 0x400000 >;             /* in zephyr/dts/arm/st/h7/stm32h7.dtsi:422 */
			interrupts = < 0x21 0x0 >,
			             < 0x22 0x0 >;                   /* in zephyr/dts/arm/st/h7/stm32h7.dtsi:423 */
			interrupt-names = "event",
			                  "error";                   /* in zephyr/dts/arm/st/h7/stm32h7.dtsi:424 */
			pinctrl-0 = < &i2c2_scl_pf1 &i2c2_sda_pf0 >; /* in workspace/hid-keyboard/boards/generic/keyboard_h723zg/keyboard_h723zg.dts:99 */
			pinctrl-names = "default";                   /* in workspace/hid-keyboard/boards/generic/keyboard_h723zg/keyboard_h723zg.dts:100 */
			status = "okay";                             /* in workspace/hid-keyboard/boards/generic/keyboard_h723zg/keyboard_h723zg.dts:101 */
			clock-frequency = < 0x61a80 >;               /* in workspace/hid-keyboard/boards/generic/keyboard_h723zg/keyboard_h723zg.dts:102 */
			phandle = < 0x1d >;                          /* in zephyr/dts/arm/st/h7/stm32h7.dtsi:1271 */
		};

		/* node '/soc/i2c@40005c00' defined in zephyr/dts/arm/st/h7/stm32h7.dtsi:428 */
		i2c3: i2c@40005c00 {
			compatible = "st,stm32-i2c-v2";  /* in zephyr/dts/arm/st/h7/stm32h7.dtsi:429 */
			clock-frequency = < 0x186a0 >;   /* in zephyr/dts/arm/st/h7/stm32h7.dtsi:430 */
			#address-cells = < 0x1 >;        /* in zephyr/dts/arm/st/h7/stm32h7.dtsi:431 */
			#size-cells = < 0x0 >;           /* in zephyr/dts/arm/st/h7/stm32h7.dtsi:432 */
			reg = < 0x40005c00 0x400 >;      /* in zephyr/dts/arm/st/h7/stm32h7.dtsi:433 */
			clocks = < &rcc 0xe8 0x800000 >; /* in zephyr/dts/arm/st/h7/stm32h7.dtsi:434 */
			interrupts = < 0x48 0x0 >,
			             < 0x49 0x0 >;       /* in zephyr/dts/arm/st/h7/stm32h7.dtsi:435 */
			interrupt-names = "event",
			                  "error";       /* in zephyr/dts/arm/st/h7/stm32h7.dtsi:436 */
			status = "disabled";             /* in zephyr/dts/arm/st/h7/stm32h7.dtsi:437 */
			phandle = < 0x1e >;              /* in zephyr/dts/arm/st/h7/stm32h7.dtsi:1279 */
		};

		/* node '/soc/i2c@58001c00' defined in zephyr/dts/arm/st/h7/stm32h7.dtsi:440 */
		i2c4: i2c@58001c00 {
			compatible = "st,stm32-i2c-v2";                /* in zephyr/dts/arm/st/h7/stm32h7.dtsi:441 */
			#address-cells = < 0x1 >;                      /* in zephyr/dts/arm/st/h7/stm32h7.dtsi:443 */
			#size-cells = < 0x0 >;                         /* in zephyr/dts/arm/st/h7/stm32h7.dtsi:444 */
			reg = < 0x58001c00 0x400 >;                    /* in zephyr/dts/arm/st/h7/stm32h7.dtsi:445 */
			clocks = < &rcc 0xf4 0x80 >;                   /* in zephyr/dts/arm/st/h7/stm32h7.dtsi:446 */
			interrupts = < 0x5f 0x0 >,
			             < 0x60 0x0 >;                     /* in zephyr/dts/arm/st/h7/stm32h7.dtsi:447 */
			interrupt-names = "event",
			                  "error";                     /* in zephyr/dts/arm/st/h7/stm32h7.dtsi:448 */
			pinctrl-0 = < &i2c4_scl_pf14 &i2c4_sda_pf15 >; /* in workspace/hid-keyboard/boards/generic/keyboard_h723zg/keyboard_h723zg.dts:92 */
			pinctrl-names = "default";                     /* in workspace/hid-keyboard/boards/generic/keyboard_h723zg/keyboard_h723zg.dts:93 */
			status = "okay";                               /* in workspace/hid-keyboard/boards/generic/keyboard_h723zg/keyboard_h723zg.dts:94 */
			clock-frequency = < 0x61a80 >;                 /* in workspace/hid-keyboard/boards/generic/keyboard_h723zg/keyboard_h723zg.dts:95 */
			phandle = < 0x1f >;                            /* in zephyr/dts/arm/st/h7/stm32h7.dtsi:1287 */
		};

		/* node '/soc/spi@40013000' defined in zephyr/dts/arm/st/h7/stm32h7.dtsi:452 */
		spi1: spi@40013000 {
			compatible = "st,stm32h7-spi",
			             "st,stm32-spi-fifo",
			             "st,stm32-spi";            /* in zephyr/dts/arm/st/h7/stm32h7.dtsi:453 */
			#address-cells = < 0x1 >;               /* in zephyr/dts/arm/st/h7/stm32h7.dtsi:454 */
			#size-cells = < 0x0 >;                  /* in zephyr/dts/arm/st/h7/stm32h7.dtsi:455 */
			reg = < 0x40013000 0x400 >;             /* in zephyr/dts/arm/st/h7/stm32h7.dtsi:456 */
			clocks = < &rcc 0xf0 0x1000 >,
			         < &rcc 0x9 0x4c0050 >;         /* in zephyr/dts/arm/st/h7/stm32h7.dtsi:457 */
			interrupts = < 0x23 0x0 >;              /* in zephyr/dts/arm/st/h7/stm32h7.dtsi:459 */
			st,spi-data-width = "full-4-to-32-bit"; /* in zephyr/dts/arm/st/h7/stm32h7.dtsi:460 */
			status = "disabled";                    /* in zephyr/dts/arm/st/h7/stm32h7.dtsi:461 */
		};

		/* node '/soc/spi@40003800' defined in zephyr/dts/arm/st/h7/stm32h7.dtsi:464 */
		spi2: spi@40003800 {
			compatible = "st,stm32h7-spi",
			             "st,stm32-spi-fifo",
			             "st,stm32-spi";            /* in zephyr/dts/arm/st/h7/stm32h7.dtsi:465 */
			#address-cells = < 0x1 >;               /* in zephyr/dts/arm/st/h7/stm32h7.dtsi:466 */
			#size-cells = < 0x0 >;                  /* in zephyr/dts/arm/st/h7/stm32h7.dtsi:467 */
			reg = < 0x40003800 0x400 >;             /* in zephyr/dts/arm/st/h7/stm32h7.dtsi:468 */
			clocks = < &rcc 0xe8 0x4000 >,
			         < &rcc 0x9 0x4c0050 >;         /* in zephyr/dts/arm/st/h7/stm32h7.dtsi:469 */
			interrupts = < 0x24 0x0 >;              /* in zephyr/dts/arm/st/h7/stm32h7.dtsi:471 */
			st,spi-data-width = "full-4-to-32-bit"; /* in zephyr/dts/arm/st/h7/stm32h7.dtsi:472 */
			status = "disabled";                    /* in zephyr/dts/arm/st/h7/stm32h7.dtsi:473 */
		};

		/* node '/soc/spi@40003c00' defined in zephyr/dts/arm/st/h7/stm32h7.dtsi:476 */
		spi3: spi@40003c00 {
			compatible = "st,stm32h7-spi",
			             "st,stm32-spi-fifo",
			             "st,stm32-spi";            /* in zephyr/dts/arm/st/h7/stm32h7.dtsi:477 */
			#address-cells = < 0x1 >;               /* in zephyr/dts/arm/st/h7/stm32h7.dtsi:478 */
			#size-cells = < 0x0 >;                  /* in zephyr/dts/arm/st/h7/stm32h7.dtsi:479 */
			reg = < 0x40003c00 0x400 >;             /* in zephyr/dts/arm/st/h7/stm32h7.dtsi:480 */
			clocks = < &rcc 0xe8 0x8000 >,
			         < &rcc 0x9 0x4c0050 >;         /* in zephyr/dts/arm/st/h7/stm32h7.dtsi:481 */
			interrupts = < 0x33 0x0 >;              /* in zephyr/dts/arm/st/h7/stm32h7.dtsi:483 */
			st,spi-data-width = "full-4-to-32-bit"; /* in zephyr/dts/arm/st/h7/stm32h7.dtsi:484 */
			status = "disabled";                    /* in zephyr/dts/arm/st/h7/stm32h7.dtsi:485 */
		};

		/* node '/soc/spi@40013400' defined in zephyr/dts/arm/st/h7/stm32h7.dtsi:488 */
		spi4: spi@40013400 {
			compatible = "st,stm32h7-spi",
			             "st,stm32-spi-fifo",
			             "st,stm32-spi";            /* in zephyr/dts/arm/st/h7/stm32h7.dtsi:489 */
			#address-cells = < 0x1 >;               /* in zephyr/dts/arm/st/h7/stm32h7.dtsi:490 */
			#size-cells = < 0x0 >;                  /* in zephyr/dts/arm/st/h7/stm32h7.dtsi:491 */
			reg = < 0x40013400 0x400 >;             /* in zephyr/dts/arm/st/h7/stm32h7.dtsi:492 */
			clocks = < &rcc 0xf0 0x2000 >;          /* in zephyr/dts/arm/st/h7/stm32h7.dtsi:493 */
			interrupts = < 0x54 0x0 >;              /* in zephyr/dts/arm/st/h7/stm32h7.dtsi:494 */
			st,spi-data-width = "full-4-to-16-bit"; /* in zephyr/dts/arm/st/h7/stm32h7.dtsi:495 */
			status = "disabled";                    /* in zephyr/dts/arm/st/h7/stm32h7.dtsi:496 */
		};

		/* node '/soc/spi@40015000' defined in zephyr/dts/arm/st/h7/stm32h7.dtsi:499 */
		spi5: spi@40015000 {
			compatible = "st,stm32h7-spi",
			             "st,stm32-spi-fifo",
			             "st,stm32-spi";            /* in zephyr/dts/arm/st/h7/stm32h7.dtsi:500 */
			#address-cells = < 0x1 >;               /* in zephyr/dts/arm/st/h7/stm32h7.dtsi:501 */
			#size-cells = < 0x0 >;                  /* in zephyr/dts/arm/st/h7/stm32h7.dtsi:502 */
			reg = < 0x40015000 0x400 >;             /* in zephyr/dts/arm/st/h7/stm32h7.dtsi:503 */
			clocks = < &rcc 0xf0 0x100000 >;        /* in zephyr/dts/arm/st/h7/stm32h7.dtsi:504 */
			interrupts = < 0x55 0x0 >;              /* in zephyr/dts/arm/st/h7/stm32h7.dtsi:505 */
			st,spi-data-width = "full-4-to-16-bit"; /* in zephyr/dts/arm/st/h7/stm32h7.dtsi:506 */
			status = "disabled";                    /* in zephyr/dts/arm/st/h7/stm32h7.dtsi:507 */
		};

		/* node '/soc/spi@58001400' defined in zephyr/dts/arm/st/h7/stm32h7.dtsi:510 */
		spi6: spi@58001400 {
			compatible = "st,stm32h7-spi",
			             "st,stm32-spi-fifo",
			             "st,stm32-spi";            /* in zephyr/dts/arm/st/h7/stm32h7.dtsi:511 */
			#address-cells = < 0x1 >;               /* in zephyr/dts/arm/st/h7/stm32h7.dtsi:512 */
			#size-cells = < 0x0 >;                  /* in zephyr/dts/arm/st/h7/stm32h7.dtsi:513 */
			reg = < 0x58001400 0x400 >;             /* in zephyr/dts/arm/st/h7/stm32h7.dtsi:514 */
			clocks = < &rcc 0xf4 0x20 >;            /* in zephyr/dts/arm/st/h7/stm32h7.dtsi:515 */
			interrupts = < 0x56 0x0 >;              /* in zephyr/dts/arm/st/h7/stm32h7.dtsi:516 */
			st,spi-data-width = "full-4-to-16-bit"; /* in zephyr/dts/arm/st/h7/stm32h7.dtsi:517 */
			status = "disabled";                    /* in zephyr/dts/arm/st/h7/stm32h7.dtsi:518 */
		};

		/* node '/soc/i2s@40013000' defined in zephyr/dts/arm/st/h7/stm32h7.dtsi:521 */
		i2s1: i2s@40013000 {
			compatible = "st,stm32h7-i2s",
			             "st,stm32-i2s";          /* in zephyr/dts/arm/st/h7/stm32h7.dtsi:522 */
			#address-cells = < 0x1 >;             /* in zephyr/dts/arm/st/h7/stm32h7.dtsi:523 */
			#size-cells = < 0x0 >;                /* in zephyr/dts/arm/st/h7/stm32h7.dtsi:524 */
			reg = < 0x40013000 0x400 >;           /* in zephyr/dts/arm/st/h7/stm32h7.dtsi:525 */
			clocks = < &rcc 0xf0 0x1000 >,
			         < &rcc 0x9 0x4c0050 >;       /* in zephyr/dts/arm/st/h7/stm32h7.dtsi:526 */
			dmas = < &dmamux1 0x0 0x26 0x20440 >,
			       < &dmamux1 0x1 0x25 0x20480 >; /* in zephyr/dts/arm/st/h7/stm32h7.dtsi:528 */
			dma-names = "tx",
			            "rx";                     /* in zephyr/dts/arm/st/h7/stm32h7.dtsi:530 */
			interrupts = < 0x23 0x3 >;            /* in zephyr/dts/arm/st/h7/stm32h7.dtsi:531 */
			status = "disabled";                  /* in zephyr/dts/arm/st/h7/stm32h7.dtsi:532 */
		};

		/* node '/soc/i2s@40003800' defined in zephyr/dts/arm/st/h7/stm32h7.dtsi:535 */
		i2s2: i2s@40003800 {
			compatible = "st,stm32h7-i2s",
			             "st,stm32-i2s";          /* in zephyr/dts/arm/st/h7/stm32h7.dtsi:536 */
			#address-cells = < 0x1 >;             /* in zephyr/dts/arm/st/h7/stm32h7.dtsi:537 */
			#size-cells = < 0x0 >;                /* in zephyr/dts/arm/st/h7/stm32h7.dtsi:538 */
			reg = < 0x40003800 0x400 >;           /* in zephyr/dts/arm/st/h7/stm32h7.dtsi:539 */
			clocks = < &rcc 0xe8 0x4000 >,
			         < &rcc 0x9 0x4c0050 >;       /* in zephyr/dts/arm/st/h7/stm32h7.dtsi:540 */
			dmas = < &dmamux1 0x0 0x28 0x20440 >,
			       < &dmamux1 0x1 0x27 0x20480 >; /* in zephyr/dts/arm/st/h7/stm32h7.dtsi:542 */
			dma-names = "tx",
			            "rx";                     /* in zephyr/dts/arm/st/h7/stm32h7.dtsi:544 */
			interrupts = < 0x24 0x0 >;            /* in zephyr/dts/arm/st/h7/stm32h7.dtsi:545 */
			status = "disabled";                  /* in zephyr/dts/arm/st/h7/stm32h7.dtsi:546 */
		};

		/* node '/soc/i2s@40003c00' defined in zephyr/dts/arm/st/h7/stm32h7.dtsi:549 */
		i2s3: i2s@40003c00 {
			compatible = "st,stm32h7-i2s",
			             "st,stm32-i2s";          /* in zephyr/dts/arm/st/h7/stm32h7.dtsi:550 */
			#address-cells = < 0x1 >;             /* in zephyr/dts/arm/st/h7/stm32h7.dtsi:551 */
			#size-cells = < 0x0 >;                /* in zephyr/dts/arm/st/h7/stm32h7.dtsi:552 */
			reg = < 0x40003c00 0x400 >;           /* in zephyr/dts/arm/st/h7/stm32h7.dtsi:553 */
			clocks = < &rcc 0xe8 0x8000 >,
			         < &rcc 0x9 0x4c0050 >;       /* in zephyr/dts/arm/st/h7/stm32h7.dtsi:554 */
			dmas = < &dmamux1 0x0 0x3e 0x20440 >,
			       < &dmamux1 0x1 0x3d 0x20480 >; /* in zephyr/dts/arm/st/h7/stm32h7.dtsi:556 */
			dma-names = "tx",
			            "rx";                     /* in zephyr/dts/arm/st/h7/stm32h7.dtsi:558 */
			interrupts = < 0x33 0x0 >;            /* in zephyr/dts/arm/st/h7/stm32h7.dtsi:559 */
			status = "disabled";                  /* in zephyr/dts/arm/st/h7/stm32h7.dtsi:560 */
		};

		/* node '/soc/can@4000a000' defined in zephyr/dts/arm/st/h7/stm32h7.dtsi:563 */
		fdcan1: can@4000a000 {
			compatible = "st,stm32h7-fdcan";                       /* in zephyr/dts/arm/st/h7/stm32h7.dtsi:564 */
			reg = < 0x4000a000 0x400 >,
			      < 0x4000ac00 0x350 >;                            /* in zephyr/dts/arm/st/h7/stm32h7.dtsi:565 */
			reg-names = "m_can",
			            "message_ram";                             /* in zephyr/dts/arm/st/h7/stm32h7.dtsi:566 */
			clocks = < &rcc 0xec 0x100 >;                          /* in zephyr/dts/arm/st/h7/stm32h7.dtsi:567 */
			interrupts = < 0x13 0x0 >,
			             < 0x15 0x0 >,
			             < 0x3f 0x0 >;                             /* in zephyr/dts/arm/st/h7/stm32h7.dtsi:568 */
			interrupt-names = "int0",
			                  "int1",
			                  "calib";                             /* in zephyr/dts/arm/st/h7/stm32h7.dtsi:569 */
			bosch,mram-cfg = < 0x0 0x1c 0x8 0x3 0x3 0x0 0x3 0x3 >; /* in zephyr/dts/arm/st/h7/stm32h7.dtsi:570 */
			status = "disabled";                                   /* in zephyr/dts/arm/st/h7/stm32h7.dtsi:571 */
		};

		/* node '/soc/can@4000a400' defined in zephyr/dts/arm/st/h7/stm32h7.dtsi:574 */
		fdcan2: can@4000a400 {
			compatible = "st,stm32h7-fdcan";                         /* in zephyr/dts/arm/st/h7/stm32h7.dtsi:575 */
			reg = < 0x4000a400 0x400 >,
			      < 0x4000ac00 0x6a0 >;                              /* in zephyr/dts/arm/st/h7/stm32h7.dtsi:576 */
			reg-names = "m_can",
			            "message_ram";                               /* in zephyr/dts/arm/st/h7/stm32h7.dtsi:577 */
			clocks = < &rcc 0xec 0x100 >;                            /* in zephyr/dts/arm/st/h7/stm32h7.dtsi:578 */
			interrupts = < 0x14 0x0 >,
			             < 0x16 0x0 >,
			             < 0x3f 0x0 >;                               /* in zephyr/dts/arm/st/h7/stm32h7.dtsi:579 */
			interrupt-names = "int0",
			                  "int1",
			                  "calib";                               /* in zephyr/dts/arm/st/h7/stm32h7.dtsi:580 */
			bosch,mram-cfg = < 0x350 0x1c 0x8 0x3 0x3 0x0 0x3 0x3 >; /* in zephyr/dts/arm/st/h7/stm32h7.dtsi:581 */
			status = "disabled";                                     /* in zephyr/dts/arm/st/h7/stm32h7.dtsi:582 */
		};

		/* node '/soc/timers@40010000' defined in zephyr/dts/arm/st/h7/stm32h7.dtsi:585 */
		timers1: timers@40010000 {
			compatible = "st,stm32-timers"; /* in zephyr/dts/arm/st/h7/stm32h7.dtsi:586 */
			reg = < 0x40010000 0x400 >;     /* in zephyr/dts/arm/st/h7/stm32h7.dtsi:587 */
			clocks = < &rcc 0xf0 0x1 >,
			         < &rcc 0x13 0xff >;    /* in zephyr/dts/arm/st/h7/stm32h7.dtsi:588 */
			resets = < &rctl 0x1300 >;      /* in zephyr/dts/arm/st/h7/stm32h7.dtsi:590 */
			interrupts = < 0x18 0x0 >,
			             < 0x19 0x0 >,
			             < 0x1a 0x0 >,
			             < 0x1b 0x0 >;      /* in zephyr/dts/arm/st/h7/stm32h7.dtsi:591 */
			interrupt-names = "brk",
			                  "up",
			                  "trgcom",
			                  "cc";         /* in zephyr/dts/arm/st/h7/stm32h7.dtsi:592 */
			st,prescaler = < 0x0 >;         /* in zephyr/dts/arm/st/h7/stm32h7.dtsi:593 */
			status = "disabled";            /* in zephyr/dts/arm/st/h7/stm32h7.dtsi:594 */

			/* node '/soc/timers@40010000/pwm' defined in zephyr/dts/arm/st/h7/stm32h7.dtsi:596 */
			pwm {
				compatible = "st,stm32-pwm"; /* in zephyr/dts/arm/st/h7/stm32h7.dtsi:597 */
				status = "disabled";         /* in zephyr/dts/arm/st/h7/stm32h7.dtsi:598 */
				#pwm-cells = < 0x3 >;        /* in zephyr/dts/arm/st/h7/stm32h7.dtsi:599 */
			};

			/* node '/soc/timers@40010000/counter' defined in zephyr/dts/arm/st/h7/stm32h7.dtsi:602 */
			counter {
				compatible = "st,stm32-counter"; /* in zephyr/dts/arm/st/h7/stm32h7.dtsi:603 */
				status = "disabled";             /* in zephyr/dts/arm/st/h7/stm32h7.dtsi:604 */
			};

			/* node '/soc/timers@40010000/qdec' defined in zephyr/dts/arm/st/h7/stm32h7.dtsi:607 */
			qdec {
				compatible = "st,stm32-qdec";    /* in zephyr/dts/arm/st/h7/stm32h7.dtsi:608 */
				st,input-filter-level = < 0x0 >; /* in zephyr/dts/arm/st/h7/stm32h7.dtsi:609 */
				status = "disabled";             /* in zephyr/dts/arm/st/h7/stm32h7.dtsi:610 */
			};
		};

		/* node '/soc/timers@40000000' defined in zephyr/dts/arm/st/h7/stm32h7.dtsi:614 */
		timers2: timers@40000000 {
			compatible = "st,stm32-timers"; /* in zephyr/dts/arm/st/h7/stm32h7.dtsi:615 */
			reg = < 0x40000000 0x400 >;     /* in zephyr/dts/arm/st/h7/stm32h7.dtsi:616 */
			clocks = < &rcc 0xe8 0x1 >,
			         < &rcc 0x12 0xff >;    /* in zephyr/dts/arm/st/h7/stm32h7.dtsi:617 */
			resets = < &rctl 0x1200 >;      /* in zephyr/dts/arm/st/h7/stm32h7.dtsi:619 */
			interrupts = < 0x1c 0x0 >;      /* in zephyr/dts/arm/st/h7/stm32h7.dtsi:620 */
			interrupt-names = "global";     /* in zephyr/dts/arm/st/h7/stm32h7.dtsi:621 */
			st,prescaler = < 0x0 >;         /* in zephyr/dts/arm/st/h7/stm32h7.dtsi:622 */
			status = "disabled";            /* in zephyr/dts/arm/st/h7/stm32h7.dtsi:623 */

			/* node '/soc/timers@40000000/pwm' defined in zephyr/dts/arm/st/h7/stm32h7.dtsi:625 */
			pwm {
				compatible = "st,stm32-pwm"; /* in zephyr/dts/arm/st/h7/stm32h7.dtsi:626 */
				status = "disabled";         /* in zephyr/dts/arm/st/h7/stm32h7.dtsi:627 */
				#pwm-cells = < 0x3 >;        /* in zephyr/dts/arm/st/h7/stm32h7.dtsi:628 */
			};

			/* node '/soc/timers@40000000/counter' defined in zephyr/dts/arm/st/h7/stm32h7.dtsi:631 */
			counter {
				compatible = "st,stm32-counter"; /* in zephyr/dts/arm/st/h7/stm32h7.dtsi:632 */
				status = "disabled";             /* in zephyr/dts/arm/st/h7/stm32h7.dtsi:633 */
			};

			/* node '/soc/timers@40000000/qdec' defined in zephyr/dts/arm/st/h7/stm32h7.dtsi:636 */
			qdec {
				compatible = "st,stm32-qdec";    /* in zephyr/dts/arm/st/h7/stm32h7.dtsi:637 */
				st,input-filter-level = < 0x0 >; /* in zephyr/dts/arm/st/h7/stm32h7.dtsi:638 */
				status = "disabled";             /* in zephyr/dts/arm/st/h7/stm32h7.dtsi:639 */
			};
		};

		/* node '/soc/timers@40000400' defined in zephyr/dts/arm/st/h7/stm32h7.dtsi:643 */
		timers3: timers@40000400 {
			compatible = "st,stm32-timers"; /* in zephyr/dts/arm/st/h7/stm32h7.dtsi:644 */
			reg = < 0x40000400 0x400 >;     /* in zephyr/dts/arm/st/h7/stm32h7.dtsi:645 */
			clocks = < &rcc 0xe8 0x2 >,
			         < &rcc 0x12 0xff >;    /* in zephyr/dts/arm/st/h7/stm32h7.dtsi:646 */
			resets = < &rctl 0x1201 >;      /* in zephyr/dts/arm/st/h7/stm32h7.dtsi:648 */
			interrupts = < 0x1d 0x0 >;      /* in zephyr/dts/arm/st/h7/stm32h7.dtsi:649 */
			interrupt-names = "global";     /* in zephyr/dts/arm/st/h7/stm32h7.dtsi:650 */
			st,prescaler = < 0x0 >;         /* in zephyr/dts/arm/st/h7/stm32h7.dtsi:651 */
			status = "disabled";            /* in zephyr/dts/arm/st/h7/stm32h7.dtsi:652 */

			/* node '/soc/timers@40000400/pwm' defined in zephyr/dts/arm/st/h7/stm32h7.dtsi:654 */
			pwm {
				compatible = "st,stm32-pwm"; /* in zephyr/dts/arm/st/h7/stm32h7.dtsi:655 */
				status = "disabled";         /* in zephyr/dts/arm/st/h7/stm32h7.dtsi:656 */
				#pwm-cells = < 0x3 >;        /* in zephyr/dts/arm/st/h7/stm32h7.dtsi:657 */
			};

			/* node '/soc/timers@40000400/counter' defined in zephyr/dts/arm/st/h7/stm32h7.dtsi:660 */
			counter {
				compatible = "st,stm32-counter"; /* in zephyr/dts/arm/st/h7/stm32h7.dtsi:661 */
				status = "disabled";             /* in zephyr/dts/arm/st/h7/stm32h7.dtsi:662 */
			};

			/* node '/soc/timers@40000400/qdec' defined in zephyr/dts/arm/st/h7/stm32h7.dtsi:665 */
			qdec {
				compatible = "st,stm32-qdec";    /* in zephyr/dts/arm/st/h7/stm32h7.dtsi:666 */
				st,input-filter-level = < 0x0 >; /* in zephyr/dts/arm/st/h7/stm32h7.dtsi:667 */
				status = "disabled";             /* in zephyr/dts/arm/st/h7/stm32h7.dtsi:668 */
			};
		};

		/* node '/soc/timers@40000800' defined in zephyr/dts/arm/st/h7/stm32h7.dtsi:672 */
		timers4: timers@40000800 {
			compatible = "st,stm32-timers"; /* in zephyr/dts/arm/st/h7/stm32h7.dtsi:673 */
			reg = < 0x40000800 0x400 >;     /* in zephyr/dts/arm/st/h7/stm32h7.dtsi:674 */
			clocks = < &rcc 0xe8 0x4 >,
			         < &rcc 0x12 0xff >;    /* in zephyr/dts/arm/st/h7/stm32h7.dtsi:675 */
			resets = < &rctl 0x1202 >;      /* in zephyr/dts/arm/st/h7/stm32h7.dtsi:677 */
			interrupts = < 0x1e 0x0 >;      /* in zephyr/dts/arm/st/h7/stm32h7.dtsi:678 */
			interrupt-names = "global";     /* in zephyr/dts/arm/st/h7/stm32h7.dtsi:679 */
			st,prescaler = < 0x0 >;         /* in zephyr/dts/arm/st/h7/stm32h7.dtsi:680 */
			status = "disabled";            /* in zephyr/dts/arm/st/h7/stm32h7.dtsi:681 */

			/* node '/soc/timers@40000800/pwm' defined in zephyr/dts/arm/st/h7/stm32h7.dtsi:683 */
			pwm {
				compatible = "st,stm32-pwm"; /* in zephyr/dts/arm/st/h7/stm32h7.dtsi:684 */
				status = "disabled";         /* in zephyr/dts/arm/st/h7/stm32h7.dtsi:685 */
				#pwm-cells = < 0x3 >;        /* in zephyr/dts/arm/st/h7/stm32h7.dtsi:686 */
			};

			/* node '/soc/timers@40000800/counter' defined in zephyr/dts/arm/st/h7/stm32h7.dtsi:689 */
			counter {
				compatible = "st,stm32-counter"; /* in zephyr/dts/arm/st/h7/stm32h7.dtsi:690 */
				status = "disabled";             /* in zephyr/dts/arm/st/h7/stm32h7.dtsi:691 */
			};

			/* node '/soc/timers@40000800/qdec' defined in zephyr/dts/arm/st/h7/stm32h7.dtsi:694 */
			qdec {
				compatible = "st,stm32-qdec";    /* in zephyr/dts/arm/st/h7/stm32h7.dtsi:695 */
				st,input-filter-level = < 0x0 >; /* in zephyr/dts/arm/st/h7/stm32h7.dtsi:696 */
				status = "disabled";             /* in zephyr/dts/arm/st/h7/stm32h7.dtsi:697 */
			};
		};

		/* node '/soc/timers@40000c00' defined in zephyr/dts/arm/st/h7/stm32h7.dtsi:701 */
		timers5: timers@40000c00 {
			compatible = "st,stm32-timers"; /* in zephyr/dts/arm/st/h7/stm32h7.dtsi:702 */
			reg = < 0x40000c00 0x400 >;     /* in zephyr/dts/arm/st/h7/stm32h7.dtsi:703 */
			clocks = < &rcc 0xe8 0x8 >,
			         < &rcc 0x12 0xff >;    /* in zephyr/dts/arm/st/h7/stm32h7.dtsi:704 */
			resets = < &rctl 0x1203 >;      /* in zephyr/dts/arm/st/h7/stm32h7.dtsi:706 */
			interrupts = < 0x32 0x0 >;      /* in zephyr/dts/arm/st/h7/stm32h7.dtsi:707 */
			interrupt-names = "global";     /* in zephyr/dts/arm/st/h7/stm32h7.dtsi:708 */
			st,prescaler = < 0x0 >;         /* in zephyr/dts/arm/st/h7/stm32h7.dtsi:709 */
			status = "disabled";            /* in zephyr/dts/arm/st/h7/stm32h7.dtsi:710 */

			/* node '/soc/timers@40000c00/pwm' defined in zephyr/dts/arm/st/h7/stm32h7.dtsi:712 */
			pwm {
				compatible = "st,stm32-pwm"; /* in zephyr/dts/arm/st/h7/stm32h7.dtsi:713 */
				status = "disabled";         /* in zephyr/dts/arm/st/h7/stm32h7.dtsi:714 */
				#pwm-cells = < 0x3 >;        /* in zephyr/dts/arm/st/h7/stm32h7.dtsi:715 */
			};

			/* node '/soc/timers@40000c00/counter' defined in zephyr/dts/arm/st/h7/stm32h7.dtsi:718 */
			counter {
				compatible = "st,stm32-counter"; /* in zephyr/dts/arm/st/h7/stm32h7.dtsi:719 */
				status = "disabled";             /* in zephyr/dts/arm/st/h7/stm32h7.dtsi:720 */
			};

			/* node '/soc/timers@40000c00/qdec' defined in zephyr/dts/arm/st/h7/stm32h7.dtsi:723 */
			qdec {
				compatible = "st,stm32-qdec";    /* in zephyr/dts/arm/st/h7/stm32h7.dtsi:724 */
				st,input-filter-level = < 0x0 >; /* in zephyr/dts/arm/st/h7/stm32h7.dtsi:725 */
				status = "disabled";             /* in zephyr/dts/arm/st/h7/stm32h7.dtsi:726 */
			};
		};

		/* node '/soc/timers@40001000' defined in zephyr/dts/arm/st/h7/stm32h7.dtsi:730 */
		timers6: timers@40001000 {
			compatible = "st,stm32-timers"; /* in zephyr/dts/arm/st/h7/stm32h7.dtsi:731 */
			reg = < 0x40001000 0x400 >;     /* in zephyr/dts/arm/st/h7/stm32h7.dtsi:732 */
			clocks = < &rcc 0xe8 0x10 >,
			         < &rcc 0x12 0xff >;    /* in zephyr/dts/arm/st/h7/stm32h7.dtsi:733 */
			resets = < &rctl 0x1204 >;      /* in zephyr/dts/arm/st/h7/stm32h7.dtsi:735 */
			interrupts = < 0x36 0x0 >;      /* in zephyr/dts/arm/st/h7/stm32h7.dtsi:736 */
			interrupt-names = "global";     /* in zephyr/dts/arm/st/h7/stm32h7.dtsi:737 */
			st,prescaler = < 0x0 >;         /* in zephyr/dts/arm/st/h7/stm32h7.dtsi:738 */
			status = "disabled";            /* in zephyr/dts/arm/st/h7/stm32h7.dtsi:739 */

			/* node '/soc/timers@40001000/counter' defined in zephyr/dts/arm/st/h7/stm32h7.dtsi:741 */
			counter {
				compatible = "st,stm32-counter"; /* in zephyr/dts/arm/st/h7/stm32h7.dtsi:742 */
				status = "disabled";             /* in zephyr/dts/arm/st/h7/stm32h7.dtsi:743 */
			};
		};

		/* node '/soc/timers@40001400' defined in zephyr/dts/arm/st/h7/stm32h7.dtsi:747 */
		timers7: timers@40001400 {
			compatible = "st,stm32-timers"; /* in zephyr/dts/arm/st/h7/stm32h7.dtsi:748 */
			reg = < 0x40001400 0x400 >;     /* in zephyr/dts/arm/st/h7/stm32h7.dtsi:749 */
			clocks = < &rcc 0xe8 0x20 >,
			         < &rcc 0x12 0xff >;    /* in zephyr/dts/arm/st/h7/stm32h7.dtsi:750 */
			resets = < &rctl 0x1205 >;      /* in zephyr/dts/arm/st/h7/stm32h7.dtsi:752 */
			interrupts = < 0x37 0x0 >;      /* in zephyr/dts/arm/st/h7/stm32h7.dtsi:753 */
			interrupt-names = "global";     /* in zephyr/dts/arm/st/h7/stm32h7.dtsi:754 */
			st,prescaler = < 0x0 >;         /* in zephyr/dts/arm/st/h7/stm32h7.dtsi:755 */
			status = "disabled";            /* in zephyr/dts/arm/st/h7/stm32h7.dtsi:756 */

			/* node '/soc/timers@40001400/counter' defined in zephyr/dts/arm/st/h7/stm32h7.dtsi:758 */
			counter {
				compatible = "st,stm32-counter"; /* in zephyr/dts/arm/st/h7/stm32h7.dtsi:759 */
				status = "disabled";             /* in zephyr/dts/arm/st/h7/stm32h7.dtsi:760 */
			};
		};

		/* node '/soc/timers@40010400' defined in zephyr/dts/arm/st/h7/stm32h7.dtsi:764 */
		timers8: timers@40010400 {
			compatible = "st,stm32-timers"; /* in zephyr/dts/arm/st/h7/stm32h7.dtsi:765 */
			reg = < 0x40010400 0x400 >;     /* in zephyr/dts/arm/st/h7/stm32h7.dtsi:766 */
			clocks = < &rcc 0xf0 0x2 >,
			         < &rcc 0x13 0xff >;    /* in zephyr/dts/arm/st/h7/stm32h7.dtsi:767 */
			resets = < &rctl 0x1301 >;      /* in zephyr/dts/arm/st/h7/stm32h7.dtsi:769 */
			interrupts = < 0x2b 0x0 >,
			             < 0x2c 0x0 >,
			             < 0x2d 0x0 >,
			             < 0x2e 0x0 >;      /* in zephyr/dts/arm/st/h7/stm32h7.dtsi:770 */
			interrupt-names = "brk",
			                  "up",
			                  "trgcom",
			                  "cc";         /* in zephyr/dts/arm/st/h7/stm32h7.dtsi:771 */
			st,prescaler = < 0x0 >;         /* in zephyr/dts/arm/st/h7/stm32h7.dtsi:772 */
			status = "disabled";            /* in zephyr/dts/arm/st/h7/stm32h7.dtsi:773 */

			/* node '/soc/timers@40010400/pwm' defined in zephyr/dts/arm/st/h7/stm32h7.dtsi:775 */
			pwm {
				compatible = "st,stm32-pwm"; /* in zephyr/dts/arm/st/h7/stm32h7.dtsi:776 */
				status = "disabled";         /* in zephyr/dts/arm/st/h7/stm32h7.dtsi:777 */
				#pwm-cells = < 0x3 >;        /* in zephyr/dts/arm/st/h7/stm32h7.dtsi:778 */
			};

			/* node '/soc/timers@40010400/counter' defined in zephyr/dts/arm/st/h7/stm32h7.dtsi:781 */
			counter {
				compatible = "st,stm32-counter"; /* in zephyr/dts/arm/st/h7/stm32h7.dtsi:782 */
				status = "disabled";             /* in zephyr/dts/arm/st/h7/stm32h7.dtsi:783 */
			};

			/* node '/soc/timers@40010400/qdec' defined in zephyr/dts/arm/st/h7/stm32h7.dtsi:786 */
			qdec {
				compatible = "st,stm32-qdec";    /* in zephyr/dts/arm/st/h7/stm32h7.dtsi:787 */
				st,input-filter-level = < 0x0 >; /* in zephyr/dts/arm/st/h7/stm32h7.dtsi:788 */
				status = "disabled";             /* in zephyr/dts/arm/st/h7/stm32h7.dtsi:789 */
			};
		};

		/* node '/soc/timers@40001800' defined in zephyr/dts/arm/st/h7/stm32h7.dtsi:793 */
		timers12: timers@40001800 {
			compatible = "st,stm32-timers"; /* in zephyr/dts/arm/st/h7/stm32h7.dtsi:794 */
			reg = < 0x40001800 0x400 >;     /* in zephyr/dts/arm/st/h7/stm32h7.dtsi:795 */
			clocks = < &rcc 0xe8 0x40 >,
			         < &rcc 0x12 0xff >;    /* in zephyr/dts/arm/st/h7/stm32h7.dtsi:796 */
			resets = < &rctl 0x1206 >;      /* in zephyr/dts/arm/st/h7/stm32h7.dtsi:798 */
			interrupts = < 0x2b 0x0 >;      /* in zephyr/dts/arm/st/h7/stm32h7.dtsi:799 */
			interrupt-names = "global";     /* in zephyr/dts/arm/st/h7/stm32h7.dtsi:800 */
			st,prescaler = < 0x0 >;         /* in zephyr/dts/arm/st/h7/stm32h7.dtsi:801 */
			status = "disabled";            /* in zephyr/dts/arm/st/h7/stm32h7.dtsi:802 */

			/* node '/soc/timers@40001800/pwm' defined in zephyr/dts/arm/st/h7/stm32h7.dtsi:804 */
			pwm {
				compatible = "st,stm32-pwm"; /* in zephyr/dts/arm/st/h7/stm32h7.dtsi:805 */
				status = "disabled";         /* in zephyr/dts/arm/st/h7/stm32h7.dtsi:806 */
				#pwm-cells = < 0x3 >;        /* in zephyr/dts/arm/st/h7/stm32h7.dtsi:807 */
			};

			/* node '/soc/timers@40001800/counter' defined in zephyr/dts/arm/st/h7/stm32h7.dtsi:810 */
			counter {
				compatible = "st,stm32-counter"; /* in zephyr/dts/arm/st/h7/stm32h7.dtsi:811 */
				status = "disabled";             /* in zephyr/dts/arm/st/h7/stm32h7.dtsi:812 */
			};
		};

		/* node '/soc/timers@40001c00' defined in zephyr/dts/arm/st/h7/stm32h7.dtsi:816 */
		timers13: timers@40001c00 {
			compatible = "st,stm32-timers"; /* in zephyr/dts/arm/st/h7/stm32h7.dtsi:817 */
			reg = < 0x40001c00 0x400 >;     /* in zephyr/dts/arm/st/h7/stm32h7.dtsi:818 */
			clocks = < &rcc 0xe8 0x80 >,
			         < &rcc 0x12 0xff >;    /* in zephyr/dts/arm/st/h7/stm32h7.dtsi:819 */
			resets = < &rctl 0x1207 >;      /* in zephyr/dts/arm/st/h7/stm32h7.dtsi:821 */
			interrupts = < 0x2c 0x0 >;      /* in zephyr/dts/arm/st/h7/stm32h7.dtsi:822 */
			interrupt-names = "global";     /* in zephyr/dts/arm/st/h7/stm32h7.dtsi:823 */
			st,prescaler = < 0x0 >;         /* in zephyr/dts/arm/st/h7/stm32h7.dtsi:824 */
			status = "disabled";            /* in zephyr/dts/arm/st/h7/stm32h7.dtsi:825 */

			/* node '/soc/timers@40001c00/pwm' defined in zephyr/dts/arm/st/h7/stm32h7.dtsi:827 */
			pwm {
				compatible = "st,stm32-pwm"; /* in zephyr/dts/arm/st/h7/stm32h7.dtsi:828 */
				status = "disabled";         /* in zephyr/dts/arm/st/h7/stm32h7.dtsi:829 */
				#pwm-cells = < 0x3 >;        /* in zephyr/dts/arm/st/h7/stm32h7.dtsi:830 */
			};

			/* node '/soc/timers@40001c00/counter' defined in zephyr/dts/arm/st/h7/stm32h7.dtsi:833 */
			counter {
				compatible = "st,stm32-counter"; /* in zephyr/dts/arm/st/h7/stm32h7.dtsi:834 */
				status = "disabled";             /* in zephyr/dts/arm/st/h7/stm32h7.dtsi:835 */
			};
		};

		/* node '/soc/timers@40002000' defined in zephyr/dts/arm/st/h7/stm32h7.dtsi:839 */
		timers14: timers@40002000 {
			compatible = "st,stm32-timers"; /* in zephyr/dts/arm/st/h7/stm32h7.dtsi:840 */
			reg = < 0x40002000 0x400 >;     /* in zephyr/dts/arm/st/h7/stm32h7.dtsi:841 */
			clocks = < &rcc 0xe8 0x100 >,
			         < &rcc 0x12 0xff >;    /* in zephyr/dts/arm/st/h7/stm32h7.dtsi:842 */
			resets = < &rctl 0x1208 >;      /* in zephyr/dts/arm/st/h7/stm32h7.dtsi:844 */
			interrupts = < 0x2d 0x0 >;      /* in zephyr/dts/arm/st/h7/stm32h7.dtsi:845 */
			interrupt-names = "global";     /* in zephyr/dts/arm/st/h7/stm32h7.dtsi:846 */
			st,prescaler = < 0x0 >;         /* in zephyr/dts/arm/st/h7/stm32h7.dtsi:847 */
			status = "disabled";            /* in zephyr/dts/arm/st/h7/stm32h7.dtsi:848 */

			/* node '/soc/timers@40002000/pwm' defined in zephyr/dts/arm/st/h7/stm32h7.dtsi:850 */
			pwm {
				compatible = "st,stm32-pwm"; /* in zephyr/dts/arm/st/h7/stm32h7.dtsi:851 */
				status = "disabled";         /* in zephyr/dts/arm/st/h7/stm32h7.dtsi:852 */
				#pwm-cells = < 0x3 >;        /* in zephyr/dts/arm/st/h7/stm32h7.dtsi:853 */
			};

			/* node '/soc/timers@40002000/counter' defined in zephyr/dts/arm/st/h7/stm32h7.dtsi:856 */
			counter {
				compatible = "st,stm32-counter"; /* in zephyr/dts/arm/st/h7/stm32h7.dtsi:857 */
				status = "disabled";             /* in zephyr/dts/arm/st/h7/stm32h7.dtsi:858 */
			};
		};

		/* node '/soc/timers@40014000' defined in zephyr/dts/arm/st/h7/stm32h7.dtsi:862 */
		timers15: timers@40014000 {
			compatible = "st,stm32-timers"; /* in zephyr/dts/arm/st/h7/stm32h7.dtsi:863 */
			reg = < 0x40014000 0x400 >;     /* in zephyr/dts/arm/st/h7/stm32h7.dtsi:864 */
			clocks = < &rcc 0xf0 0x10000 >,
			         < &rcc 0x13 0xff >;    /* in zephyr/dts/arm/st/h7/stm32h7.dtsi:865 */
			resets = < &rctl 0x1310 >;      /* in zephyr/dts/arm/st/h7/stm32h7.dtsi:867 */
			interrupts = < 0x74 0x0 >;      /* in zephyr/dts/arm/st/h7/stm32h7.dtsi:868 */
			interrupt-names = "global";     /* in zephyr/dts/arm/st/h7/stm32h7.dtsi:869 */
			st,prescaler = < 0x0 >;         /* in zephyr/dts/arm/st/h7/stm32h7.dtsi:870 */
			status = "disabled";            /* in zephyr/dts/arm/st/h7/stm32h7.dtsi:871 */

			/* node '/soc/timers@40014000/pwm' defined in zephyr/dts/arm/st/h7/stm32h7.dtsi:873 */
			pwm {
				compatible = "st,stm32-pwm"; /* in zephyr/dts/arm/st/h7/stm32h7.dtsi:874 */
				status = "disabled";         /* in zephyr/dts/arm/st/h7/stm32h7.dtsi:875 */
				#pwm-cells = < 0x3 >;        /* in zephyr/dts/arm/st/h7/stm32h7.dtsi:876 */
			};

			/* node '/soc/timers@40014000/counter' defined in zephyr/dts/arm/st/h7/stm32h7.dtsi:879 */
			counter {
				compatible = "st,stm32-counter"; /* in zephyr/dts/arm/st/h7/stm32h7.dtsi:880 */
				status = "disabled";             /* in zephyr/dts/arm/st/h7/stm32h7.dtsi:881 */
			};
		};

		/* node '/soc/timers@40014400' defined in zephyr/dts/arm/st/h7/stm32h7.dtsi:885 */
		timers16: timers@40014400 {
			compatible = "st,stm32-timers"; /* in zephyr/dts/arm/st/h7/stm32h7.dtsi:886 */
			reg = < 0x40014400 0x400 >;     /* in zephyr/dts/arm/st/h7/stm32h7.dtsi:887 */
			clocks = < &rcc 0xf0 0x20000 >,
			         < &rcc 0x13 0xff >;    /* in zephyr/dts/arm/st/h7/stm32h7.dtsi:888 */
			resets = < &rctl 0x1311 >;      /* in zephyr/dts/arm/st/h7/stm32h7.dtsi:890 */
			interrupts = < 0x75 0x0 >;      /* in zephyr/dts/arm/st/h7/stm32h7.dtsi:891 */
			interrupt-names = "global";     /* in zephyr/dts/arm/st/h7/stm32h7.dtsi:892 */
			st,prescaler = < 0x0 >;         /* in zephyr/dts/arm/st/h7/stm32h7.dtsi:893 */
			status = "disabled";            /* in zephyr/dts/arm/st/h7/stm32h7.dtsi:894 */

			/* node '/soc/timers@40014400/pwm' defined in zephyr/dts/arm/st/h7/stm32h7.dtsi:896 */
			pwm {
				compatible = "st,stm32-pwm"; /* in zephyr/dts/arm/st/h7/stm32h7.dtsi:897 */
				status = "disabled";         /* in zephyr/dts/arm/st/h7/stm32h7.dtsi:898 */
				#pwm-cells = < 0x3 >;        /* in zephyr/dts/arm/st/h7/stm32h7.dtsi:899 */
			};

			/* node '/soc/timers@40014400/counter' defined in zephyr/dts/arm/st/h7/stm32h7.dtsi:902 */
			counter {
				compatible = "st,stm32-counter"; /* in zephyr/dts/arm/st/h7/stm32h7.dtsi:903 */
				status = "disabled";             /* in zephyr/dts/arm/st/h7/stm32h7.dtsi:904 */
			};
		};

		/* node '/soc/timers@40014800' defined in zephyr/dts/arm/st/h7/stm32h7.dtsi:908 */
		timers17: timers@40014800 {
			compatible = "st,stm32-timers"; /* in zephyr/dts/arm/st/h7/stm32h7.dtsi:909 */
			reg = < 0x40014800 0x400 >;     /* in zephyr/dts/arm/st/h7/stm32h7.dtsi:910 */
			clocks = < &rcc 0xf0 0x40000 >,
			         < &rcc 0x13 0xff >;    /* in zephyr/dts/arm/st/h7/stm32h7.dtsi:911 */
			resets = < &rctl 0x1312 >;      /* in zephyr/dts/arm/st/h7/stm32h7.dtsi:913 */
			interrupts = < 0x76 0x0 >;      /* in zephyr/dts/arm/st/h7/stm32h7.dtsi:914 */
			interrupt-names = "global";     /* in zephyr/dts/arm/st/h7/stm32h7.dtsi:915 */
			st,prescaler = < 0x0 >;         /* in zephyr/dts/arm/st/h7/stm32h7.dtsi:916 */
			status = "disabled";            /* in zephyr/dts/arm/st/h7/stm32h7.dtsi:917 */

			/* node '/soc/timers@40014800/pwm' defined in zephyr/dts/arm/st/h7/stm32h7.dtsi:919 */
			pwm {
				compatible = "st,stm32-pwm"; /* in zephyr/dts/arm/st/h7/stm32h7.dtsi:920 */
				status = "disabled";         /* in zephyr/dts/arm/st/h7/stm32h7.dtsi:921 */
				#pwm-cells = < 0x3 >;        /* in zephyr/dts/arm/st/h7/stm32h7.dtsi:922 */
			};

			/* node '/soc/timers@40014800/counter' defined in zephyr/dts/arm/st/h7/stm32h7.dtsi:925 */
			counter {
				compatible = "st,stm32-counter"; /* in zephyr/dts/arm/st/h7/stm32h7.dtsi:926 */
				status = "disabled";             /* in zephyr/dts/arm/st/h7/stm32h7.dtsi:927 */
			};
		};

		/* node '/soc/timers@40002400' defined in zephyr/dts/arm/st/h7/stm32h7.dtsi:931 */
		lptim1: timers@40002400 {
			compatible = "st,stm32-lptim"; /* in zephyr/dts/arm/st/h7/stm32h7.dtsi:932 */
			clocks = < &rcc 0xe8 0x200 >;  /* in zephyr/dts/arm/st/h7/stm32h7.dtsi:933 */
			resets = < &rctl 0x1209 >;     /* in zephyr/dts/arm/st/h7/stm32h7.dtsi:934 */
			#address-cells = < 0x1 >;      /* in zephyr/dts/arm/st/h7/stm32h7.dtsi:935 */
			#size-cells = < 0x0 >;         /* in zephyr/dts/arm/st/h7/stm32h7.dtsi:936 */
			reg = < 0x40002400 0x400 >;    /* in zephyr/dts/arm/st/h7/stm32h7.dtsi:937 */
			interrupts = < 0x5d 0x1 >;     /* in zephyr/dts/arm/st/h7/stm32h7.dtsi:938 */
			interrupt-names = "wakeup";    /* in zephyr/dts/arm/st/h7/stm32h7.dtsi:939 */
			status = "disabled";           /* in zephyr/dts/arm/st/h7/stm32h7.dtsi:940 */
		};

		/* node '/soc/adc@40022000' defined in zephyr/dts/arm/st/h7/stm32h7.dtsi:943 */
		adc1: adc@40022000 {
			compatible = "st,stm32-adc";                                 /* in zephyr/dts/arm/st/h7/stm32h7.dtsi:944 */
			reg = < 0x40022000 0x400 >;                                  /* in zephyr/dts/arm/st/h7/stm32h7.dtsi:945 */
			clocks = < &rcc 0xd8 0x20 >;                                 /* in zephyr/dts/arm/st/h7/stm32h7.dtsi:946 */
			clock-names = "adcx";                                        /* in zephyr/dts/arm/st/h7/stm32h7.dtsi:947 */
			interrupts = < 0x12 0x0 >;                                   /* in zephyr/dts/arm/st/h7/stm32h7.dtsi:948 */
			#io-channel-cells = < 0x1 >;                                 /* in zephyr/dts/arm/st/h7/stm32h7.dtsi:949 */
			st,adc-resolutions = < 0x10 0xe 0xc 0xa 0x8 >;               /* in zephyr/dts/arm/st/h7/stm32h7.dtsi:950 */
			sampling-times = < 0x2 0x3 0x9 0x11 0x21 0x41 0x184 0x32b >; /* in zephyr/dts/arm/st/h7/stm32h7.dtsi:951 */
			st,adc-sequencer = "programmable";                           /* in zephyr/dts/arm/st/h7/stm32h7.dtsi:952 */
			st,adc-oversampler = "extended";                             /* in zephyr/dts/arm/st/h7/stm32h7.dtsi:953 */
			st,adc-internal-regulator = "startup-hw-status";             /* in zephyr/dts/arm/st/h7/stm32h7.dtsi:954 */
			st,adc-has-deep-powerdown;                                   /* in zephyr/dts/arm/st/h7/stm32h7.dtsi:955 */
			st,adc-has-channel-preselection;                             /* in zephyr/dts/arm/st/h7/stm32h7.dtsi:956 */
			st,adc-has-differential-support;                             /* in zephyr/dts/arm/st/h7/stm32h7.dtsi:957 */
			status = "disabled";                                         /* in zephyr/dts/arm/st/h7/stm32h7.dtsi:958 */
		};

		/* node '/soc/adc@40022100' defined in zephyr/dts/arm/st/h7/stm32h7.dtsi:961 */
		adc2: adc@40022100 {
			compatible = "st,stm32-adc";                                 /* in zephyr/dts/arm/st/h7/stm32h7.dtsi:962 */
			reg = < 0x40022100 0x400 >;                                  /* in zephyr/dts/arm/st/h7/stm32h7.dtsi:963 */
			clocks = < &rcc 0xd8 0x20 >;                                 /* in zephyr/dts/arm/st/h7/stm32h7.dtsi:964 */
			clock-names = "adcx";                                        /* in zephyr/dts/arm/st/h7/stm32h7.dtsi:965 */
			interrupts = < 0x12 0x0 >;                                   /* in zephyr/dts/arm/st/h7/stm32h7.dtsi:966 */
			#io-channel-cells = < 0x1 >;                                 /* in zephyr/dts/arm/st/h7/stm32h7.dtsi:967 */
			st,adc-resolutions = < 0x10 0xe 0xc 0xa 0x8 >;               /* in zephyr/dts/arm/st/h7/stm32h7.dtsi:968 */
			sampling-times = < 0x2 0x3 0x9 0x11 0x21 0x41 0x184 0x32b >; /* in zephyr/dts/arm/st/h7/stm32h7.dtsi:969 */
			st,adc-sequencer = "programmable";                           /* in zephyr/dts/arm/st/h7/stm32h7.dtsi:970 */
			st,adc-oversampler = "extended";                             /* in zephyr/dts/arm/st/h7/stm32h7.dtsi:971 */
			st,adc-internal-regulator = "startup-hw-status";             /* in zephyr/dts/arm/st/h7/stm32h7.dtsi:972 */
			st,adc-has-deep-powerdown;                                   /* in zephyr/dts/arm/st/h7/stm32h7.dtsi:973 */
			st,adc-has-channel-preselection;                             /* in zephyr/dts/arm/st/h7/stm32h7.dtsi:974 */
			st,adc-has-differential-support;                             /* in zephyr/dts/arm/st/h7/stm32h7.dtsi:975 */
			status = "disabled";                                         /* in zephyr/dts/arm/st/h7/stm32h7.dtsi:976 */
		};

		/* node '/soc/adc@40022300' defined in zephyr/dts/arm/st/h7/stm32h7.dtsi:980 */
		adc1_2: adc@40022300 {
			compatible = "st,stm32-adc";                                 /* in zephyr/dts/arm/st/h7/stm32h7.dtsi:981 */
			reg = < 0x40022300 0x400 >;                                  /* in zephyr/dts/arm/st/h7/stm32h7.dtsi:982 */
			clocks = < &rcc 0xd8 0x20 >;                                 /* in zephyr/dts/arm/st/h7/stm32h7.dtsi:983 */
			clock-names = "adcx";                                        /* in zephyr/dts/arm/st/h7/stm32h7.dtsi:984 */
			interrupts = < 0x12 0x0 >;                                   /* in zephyr/dts/arm/st/h7/stm32h7.dtsi:985 */
			#io-channel-cells = < 0x1 >;                                 /* in zephyr/dts/arm/st/h7/stm32h7.dtsi:986 */
			st,adc-resolutions = < 0x10 0xe 0xc 0xa 0x8 >;               /* in zephyr/dts/arm/st/h7/stm32h7.dtsi:987 */
			sampling-times = < 0x2 0x3 0x9 0x11 0x21 0x41 0x184 0x32b >; /* in zephyr/dts/arm/st/h7/stm32h7.dtsi:988 */
			st,adc-sequencer = "programmable";                           /* in zephyr/dts/arm/st/h7/stm32h7.dtsi:989 */
			st,adc-oversampler = "extended";                             /* in zephyr/dts/arm/st/h7/stm32h7.dtsi:990 */
			st,adc-internal-regulator = "startup-hw-status";             /* in zephyr/dts/arm/st/h7/stm32h7.dtsi:991 */
			st,adc-has-deep-powerdown;                                   /* in zephyr/dts/arm/st/h7/stm32h7.dtsi:992 */
			st,adc-has-channel-preselection;                             /* in zephyr/dts/arm/st/h7/stm32h7.dtsi:993 */
			st,adc-has-differential-support;                             /* in zephyr/dts/arm/st/h7/stm32h7.dtsi:994 */
			status = "disabled";                                         /* in zephyr/dts/arm/st/h7/stm32h7.dtsi:995 */
		};

		/* node '/soc/adc@58026000' defined in zephyr/dts/arm/st/h7/stm32h7.dtsi:998 */
		adc3: adc@58026000 {
			compatible = "st,stm32-adc";                                /* in zephyr/dts/arm/st/h7/stm32h7.dtsi:999 */
			reg = < 0x58026000 0x400 >;                                 /* in zephyr/dts/arm/st/h7/stm32h7.dtsi:1000 */
			clocks = < &rcc 0xe0 0x1000000 >;                           /* in zephyr/dts/arm/st/h7/stm32h7.dtsi:1001 */
			clock-names = "adcx";                                       /* in zephyr/dts/arm/st/h7/stm32h7.dtsi:1002 */
			interrupts = < 0x7f 0x0 >;                                  /* in zephyr/dts/arm/st/h7/stm32h7.dtsi:1003 */
			#io-channel-cells = < 0x1 >;                                /* in zephyr/dts/arm/st/h7/stm32h7.dtsi:1004 */
			st,adc-sequencer = "programmable";                          /* in zephyr/dts/arm/st/h7/stm32h7.dtsi:1007 */
			st,adc-has-deep-powerdown;                                  /* in zephyr/dts/arm/st/h7/stm32h7.dtsi:1010 */
			st,adc-has-channel-preselection;                            /* in zephyr/dts/arm/st/h7/stm32h7.dtsi:1011 */
			st,adc-has-differential-support;                            /* in zephyr/dts/arm/st/h7/stm32h7.dtsi:1012 */
			status = "disabled";                                        /* in zephyr/dts/arm/st/h7/stm32h7.dtsi:1013 */
			st,adc-resolutions = < 0xc 0xa 0x8 0x6 >;                   /* in zephyr/dts/arm/st/h7/stm32h723.dtsi:50 */
			sampling-times = < 0x3 0x7 0xd 0x19 0x30 0x5d 0xf8 0x281 >; /* in zephyr/dts/arm/st/h7/stm32h723.dtsi:51 */
			st,adc-oversampler = "minimal";                             /* in zephyr/dts/arm/st/h7/stm32h723.dtsi:52 */
			st,adc-internal-regulator = "startup-sw-delay";             /* in zephyr/dts/arm/st/h7/stm32h723.dtsi:53 */
			phandle = < 0x1b >;                                         /* in zephyr/dts/arm/st/h7/stm32h723.dtsi:240 */
		};

		/* node '/soc/dac@40007400' defined in zephyr/dts/arm/st/h7/stm32h7.dtsi:1016 */
		dac1: dac@40007400 {
			compatible = "st,stm32-dac";       /* in zephyr/dts/arm/st/h7/stm32h7.dtsi:1017 */
			reg = < 0x40007400 0x400 >;        /* in zephyr/dts/arm/st/h7/stm32h7.dtsi:1018 */
			clocks = < &rcc 0xe8 0x20000000 >; /* in zephyr/dts/arm/st/h7/stm32h7.dtsi:1019 */
			status = "disabled";               /* in zephyr/dts/arm/st/h7/stm32h7.dtsi:1020 */
			#io-channel-cells = < 0x1 >;       /* in zephyr/dts/arm/st/h7/stm32h7.dtsi:1021 */
		};

		/* node '/soc/dma@40020000' defined in zephyr/dts/arm/st/h7/stm32h7.dtsi:1024 */
		dma1: dma@40020000 {
			compatible = "st,stm32-dma-v1"; /* in zephyr/dts/arm/st/h7/stm32h7.dtsi:1025 */
			#dma-cells = < 0x4 >;           /* in zephyr/dts/arm/st/h7/stm32h7.dtsi:1026 */
			reg = < 0x40020000 0x400 >;     /* in zephyr/dts/arm/st/h7/stm32h7.dtsi:1027 */
			interrupts = < 0xb 0x0 >,
			             < 0xc 0x0 >,
			             < 0xd 0x0 >,
			             < 0xe 0x0 >,
			             < 0xf 0x0 >,
			             < 0x10 0x0 >,
			             < 0x11 0x0 >,
			             < 0x2f 0x0 >;      /* in zephyr/dts/arm/st/h7/stm32h7.dtsi:1028 */
			clocks = < &rcc 0xd8 0x1 >;     /* in zephyr/dts/arm/st/h7/stm32h7.dtsi:1030 */
			st,mem2mem;                     /* in zephyr/dts/arm/st/h7/stm32h7.dtsi:1031 */
			dma-offset = < 0x0 >;           /* in zephyr/dts/arm/st/h7/stm32h7.dtsi:1032 */
			dma-requests = < 0x8 >;         /* in zephyr/dts/arm/st/h7/stm32h7.dtsi:1033 */
			status = "disabled";            /* in zephyr/dts/arm/st/h7/stm32h7.dtsi:1034 */
			phandle = < 0xc >;              /* in zephyr/dts/arm/st/h7/stm32h7.dtsi:1184 */
		};

		/* node '/soc/dma@40020400' defined in zephyr/dts/arm/st/h7/stm32h7.dtsi:1037 */
		dma2: dma@40020400 {
			compatible = "st,stm32-dma-v1"; /* in zephyr/dts/arm/st/h7/stm32h7.dtsi:1038 */
			#dma-cells = < 0x4 >;           /* in zephyr/dts/arm/st/h7/stm32h7.dtsi:1039 */
			reg = < 0x40020400 0x400 >;     /* in zephyr/dts/arm/st/h7/stm32h7.dtsi:1040 */
			interrupts = < 0x38 0x0 >,
			             < 0x39 0x0 >,
			             < 0x3a 0x0 >,
			             < 0x3b 0x0 >,
			             < 0x3c 0x0 >,
			             < 0x44 0x0 >,
			             < 0x45 0x0 >,
			             < 0x46 0x0 >;      /* in zephyr/dts/arm/st/h7/stm32h7.dtsi:1041 */
			clocks = < &rcc 0xd8 0x2 >;     /* in zephyr/dts/arm/st/h7/stm32h7.dtsi:1043 */
			st,mem2mem;                     /* in zephyr/dts/arm/st/h7/stm32h7.dtsi:1044 */
			dma-offset = < 0x8 >;           /* in zephyr/dts/arm/st/h7/stm32h7.dtsi:1045 */
			dma-requests = < 0x8 >;         /* in zephyr/dts/arm/st/h7/stm32h7.dtsi:1046 */
			status = "disabled";            /* in zephyr/dts/arm/st/h7/stm32h7.dtsi:1047 */
		};

		/* node '/soc/bdma@58025400' defined in zephyr/dts/arm/st/h7/stm32h7.dtsi:1050 */
		bdma1: bdma@58025400 {
			compatible = "st,stm32-bdma";    /* in zephyr/dts/arm/st/h7/stm32h7.dtsi:1051 */
			#dma-cells = < 0x4 >;            /* in zephyr/dts/arm/st/h7/stm32h7.dtsi:1052 */
			reg = < 0x58025400 0x400 >;      /* in zephyr/dts/arm/st/h7/stm32h7.dtsi:1053 */
			interrupts = < 0x81 0x0 >,
			             < 0x82 0x0 >,
			             < 0x83 0x0 >,
			             < 0x84 0x0 >,
			             < 0x85 0x0 >,
			             < 0x86 0x0 >,
			             < 0x87 0x0 >,
			             < 0x88 0x0 >;       /* in zephyr/dts/arm/st/h7/stm32h7.dtsi:1054 */
			clocks = < &rcc 0xe0 0x200000 >; /* in zephyr/dts/arm/st/h7/stm32h7.dtsi:1056 */
			st,mem2mem;                      /* in zephyr/dts/arm/st/h7/stm32h7.dtsi:1057 */
			dma-offset = < 0x0 >;            /* in zephyr/dts/arm/st/h7/stm32h7.dtsi:1058 */
			dma-requests = < 0x8 >;          /* in zephyr/dts/arm/st/h7/stm32h7.dtsi:1059 */
			status = "disabled";             /* in zephyr/dts/arm/st/h7/stm32h7.dtsi:1060 */
		};

		/* node '/soc/dmamux@40020800' defined in zephyr/dts/arm/st/h7/stm32h7.dtsi:1063 */
		dmamux1: dmamux@40020800 {
			compatible = "st,stm32-dmamux"; /* in zephyr/dts/arm/st/h7/stm32h7.dtsi:1064 */
			#dma-cells = < 0x3 >;           /* in zephyr/dts/arm/st/h7/stm32h7.dtsi:1065 */
			reg = < 0x40020800 0x400 >;     /* in zephyr/dts/arm/st/h7/stm32h7.dtsi:1066 */
			interrupts = < 0x66 0x0 >;      /* in zephyr/dts/arm/st/h7/stm32h7.dtsi:1067 */
			clocks = < &rcc 0xd8 0x1 >;     /* in zephyr/dts/arm/st/h7/stm32h7.dtsi:1069 */
			dma-channels = < 0x10 >;        /* in zephyr/dts/arm/st/h7/stm32h7.dtsi:1070 */
			dma-generators = < 0x8 >;       /* in zephyr/dts/arm/st/h7/stm32h7.dtsi:1071 */
			status = "disabled";            /* in zephyr/dts/arm/st/h7/stm32h7.dtsi:1072 */
			dma-requests = < 0x81 >;        /* in zephyr/dts/arm/st/h7/stm32h723.dtsi:57 */
			phandle = < 0xa >;              /* in zephyr/dts/arm/st/h7/stm32h7.dtsi:528 */
		};

		/* node '/soc/dmamux@58025800' defined in zephyr/dts/arm/st/h7/stm32h7.dtsi:1079 */
		dmamux2: dmamux@58025800 {
			compatible = "st,stm32-dmamux";  /* in zephyr/dts/arm/st/h7/stm32h7.dtsi:1080 */
			#dma-cells = < 0x3 >;            /* in zephyr/dts/arm/st/h7/stm32h7.dtsi:1081 */
			reg = < 0x58025800 0x400 >;      /* in zephyr/dts/arm/st/h7/stm32h7.dtsi:1082 */
			interrupts = < 0x80 0x0 >;       /* in zephyr/dts/arm/st/h7/stm32h7.dtsi:1083 */
			clocks = < &rcc 0xe0 0x200000 >; /* in zephyr/dts/arm/st/h7/stm32h7.dtsi:1085 */
			dma-channels = < 0x8 >;          /* in zephyr/dts/arm/st/h7/stm32h7.dtsi:1086 */
			dma-generators = < 0x8 >;        /* in zephyr/dts/arm/st/h7/stm32h7.dtsi:1087 */
			status = "disabled";             /* in zephyr/dts/arm/st/h7/stm32h7.dtsi:1088 */
			dma-requests = < 0x81 >;         /* in zephyr/dts/arm/st/h7/stm32h723.dtsi:61 */
		};

		/* node '/soc/rng@48021800' defined in zephyr/dts/arm/st/h7/stm32h7.dtsi:1095 */
		rng: rng@48021800 {
			compatible = "st,stm32-rng";        /* in zephyr/dts/arm/st/h7/stm32h7.dtsi:1096 */
			reg = < 0x48021800 0x400 >;         /* in zephyr/dts/arm/st/h7/stm32h7.dtsi:1097 */
			clocks = < &rcc 0xdc 0x40 >;        /* in zephyr/dts/arm/st/h7/stm32h7.dtsi:1098 */
			interrupts = < 0x50 0x0 >;          /* in zephyr/dts/arm/st/h7/stm32h7.dtsi:1099 */
			status = "disabled";                /* in zephyr/dts/arm/st/h7/stm32h7.dtsi:1100 */
			nist-config = < 0xf00d00 >;         /* in zephyr/dts/arm/st/h7/stm32h723.dtsi:65 */
			health-test-magic = < 0x17590abc >; /* in zephyr/dts/arm/st/h7/stm32h723.dtsi:66 */
			health-test-config = < 0xaa74 >;    /* in zephyr/dts/arm/st/h7/stm32h723.dtsi:67 */
		};

		/* node '/soc/sdmmc@52007000' defined in zephyr/dts/arm/st/h7/stm32h7.dtsi:1103 */
		sdmmc1: sdmmc@52007000 {
			compatible = "st,stm32-sdmmc";  /* in zephyr/dts/arm/st/h7/stm32h7.dtsi:1104 */
			reg = < 0x52007000 0x400 >;     /* in zephyr/dts/arm/st/h7/stm32h7.dtsi:1105 */
			clocks = < &rcc 0xd4 0x10000 >,
			         < &rcc 0x9 0x10004c >; /* in zephyr/dts/arm/st/h7/stm32h7.dtsi:1106 */
			resets = < &rctl 0xf90 >;       /* in zephyr/dts/arm/st/h7/stm32h7.dtsi:1108 */
			interrupts = < 0x31 0x0 >;      /* in zephyr/dts/arm/st/h7/stm32h7.dtsi:1109 */
			status = "disabled";            /* in zephyr/dts/arm/st/h7/stm32h7.dtsi:1110 */
		};

		/* node '/soc/sdmmc@48022400' defined in zephyr/dts/arm/st/h7/stm32h7.dtsi:1113 */
		sdmmc2: sdmmc@48022400 {
			compatible = "st,stm32-sdmmc";  /* in zephyr/dts/arm/st/h7/stm32h7.dtsi:1114 */
			reg = < 0x48022400 0x400 >;     /* in zephyr/dts/arm/st/h7/stm32h7.dtsi:1115 */
			clocks = < &rcc 0xdc 0x200 >,
			         < &rcc 0x9 0x10004c >; /* in zephyr/dts/arm/st/h7/stm32h7.dtsi:1116 */
			resets = < &rctl 0x1089 >;      /* in zephyr/dts/arm/st/h7/stm32h7.dtsi:1118 */
			interrupts = < 0x7c 0x0 >;      /* in zephyr/dts/arm/st/h7/stm32h7.dtsi:1119 */
			status = "disabled";            /* in zephyr/dts/arm/st/h7/stm32h7.dtsi:1120 */
		};

		/* node '/soc/ethernet@40028000' defined in zephyr/dts/arm/st/h7/stm32h7.dtsi:1123 */
		ethernet@40028000 {
			reg = < 0x40028000 0x8000 >;                 /* in zephyr/dts/arm/st/h7/stm32h7.dtsi:1124 */
			compatible = "st,stm32-ethernet-controller"; /* in zephyr/dts/arm/st/h7/stm32h7.dtsi:1125 */
			clock-names = "stm-eth",
			              "mac-clk-tx",
			              "mac-clk-rx";                  /* in zephyr/dts/arm/st/h7/stm32h7.dtsi:1126 */
			clocks = < &rcc 0xd8 0x8000 >,
			         < &rcc 0xd8 0x10000 >,
			         < &rcc 0xd8 0x20000 >;              /* in zephyr/dts/arm/st/h7/stm32h7.dtsi:1127 */

			/* node '/soc/ethernet@40028000/ethernet' defined in zephyr/dts/arm/st/h7/stm32h7.dtsi:1131 */
			mac: ethernet {
				compatible = "st,stm32h7-ethernet",
				             "st,stm32-ethernet";   /* in zephyr/dts/arm/st/h7/stm32h7.dtsi:1132 */
				interrupts = < 0x3d 0x0 >;          /* in zephyr/dts/arm/st/h7/stm32h7.dtsi:1133 */
				memory-regions = < &sram2 >;        /* in zephyr/dts/arm/st/h7/stm32h7.dtsi:1134 */
				status = "disabled";                /* in zephyr/dts/arm/st/h7/stm32h7.dtsi:1135 */
			};

			/* node '/soc/ethernet@40028000/mdio' defined in zephyr/dts/arm/st/h7/stm32h7.dtsi:1138 */
			mdio: mdio {
				compatible = "st,stm32-mdio"; /* in zephyr/dts/arm/st/h7/stm32h7.dtsi:1139 */
				#address-cells = < 0x1 >;     /* in zephyr/dts/arm/st/h7/stm32h7.dtsi:1140 */
				#size-cells = < 0x0 >;        /* in zephyr/dts/arm/st/h7/stm32h7.dtsi:1141 */
				status = "disabled";          /* in zephyr/dts/arm/st/h7/stm32h7.dtsi:1142 */
			};
		};

		/* node '/soc/memory-controller@52004000' defined in zephyr/dts/arm/st/h7/stm32h7.dtsi:1146 */
		fmc: memory-controller@52004000 {
			compatible = "st,stm32h7-fmc"; /* in zephyr/dts/arm/st/h7/stm32h7.dtsi:1147 */
			reg = < 0x52004000 0x400 >;    /* in zephyr/dts/arm/st/h7/stm32h7.dtsi:1148 */
			clocks = < &rcc 0xd4 0x1000 >; /* in zephyr/dts/arm/st/h7/stm32h7.dtsi:1149 */
			status = "disabled";           /* in zephyr/dts/arm/st/h7/stm32h7.dtsi:1150 */

			/* node '/soc/memory-controller@52004000/sdram' defined in zephyr/dts/arm/st/h7/stm32h7.dtsi:1152 */
			sdram: sdram {
				compatible = "st,stm32-fmc-sdram"; /* in zephyr/dts/arm/st/h7/stm32h7.dtsi:1153 */
				#address-cells = < 0x1 >;          /* in zephyr/dts/arm/st/h7/stm32h7.dtsi:1154 */
				#size-cells = < 0x0 >;             /* in zephyr/dts/arm/st/h7/stm32h7.dtsi:1155 */
				status = "disabled";               /* in zephyr/dts/arm/st/h7/stm32h7.dtsi:1156 */
			};
		};

		/* node '/soc/memory@38800000' defined in zephyr/dts/arm/st/h7/stm32h7.dtsi:1160 */
		backup_sram: memory@38800000 {
			compatible = "zephyr,memory-region",
			             "st,stm32-backup-sram";  /* in zephyr/dts/arm/st/h7/stm32h7.dtsi:1161 */
			reg = < 0x38800000 0x1000 >;          /* in zephyr/dts/arm/st/h7/stm32h7.dtsi:1162 */
			clocks = < &rcc 0xe0 0x10000000 >;    /* in zephyr/dts/arm/st/h7/stm32h7.dtsi:1163 */
			zephyr,memory-region = "BACKUP_SRAM"; /* in zephyr/dts/arm/st/h7/stm32h7.dtsi:1164 */
			status = "disabled";                  /* in zephyr/dts/arm/st/h7/stm32h7.dtsi:1165 */
		};

		/* node '/soc/spi@52005000' defined in zephyr/dts/arm/st/h7/stm32h7.dtsi:1168 */
		quadspi: octospi1: spi@52005000 {
			compatible = "st,stm32-ospi";    /* in zephyr/dts/arm/st/h7/stm32h723.dtsi:95 */
			reg = < 0x52005000 0x1000 >,
			      < 0x90000000 0x10000000 >; /* in zephyr/dts/arm/st/h7/stm32h723.dtsi:96 */
			interrupts = < 0x5c 0x0 >;       /* in zephyr/dts/arm/st/h7/stm32h723.dtsi:97 */
			clock-names = "ospix",
			              "ospi-ker";        /* in zephyr/dts/arm/st/h7/stm32h723.dtsi:98 */
			clocks = < &rcc 0xd4 0x4000 >,
			         < &rcc 0x9 0x124004c >; /* in zephyr/dts/arm/st/h7/stm32h723.dtsi:99 */
			#address-cells = < 0x1 >;        /* in zephyr/dts/arm/st/h7/stm32h723.dtsi:101 */
			#size-cells = < 0x0 >;           /* in zephyr/dts/arm/st/h7/stm32h723.dtsi:102 */
			status = "disabled";             /* in zephyr/dts/arm/st/h7/stm32h723.dtsi:103 */
		};

		/* node '/soc/dcmi@48020000' defined in zephyr/dts/arm/st/h7/stm32h7.dtsi:1178 */
		dcmi: dcmi@48020000 {
			compatible = "st,stm32-dcmi";          /* in zephyr/dts/arm/st/h7/stm32h7.dtsi:1179 */
			reg = < 0x48020000 0x400 >;            /* in zephyr/dts/arm/st/h7/stm32h7.dtsi:1180 */
			interrupts = < 0x4e 0x0 >;             /* in zephyr/dts/arm/st/h7/stm32h7.dtsi:1181 */
			interrupt-names = "dcmi";              /* in zephyr/dts/arm/st/h7/stm32h7.dtsi:1182 */
			clocks = < &rcc 0xdc 0x1 >;            /* in zephyr/dts/arm/st/h7/stm32h7.dtsi:1183 */
			dmas = < &dma1 0x1 0x4b 0x24480 0x0 >; /* in zephyr/dts/arm/st/h7/stm32h7.dtsi:1184 */
			status = "disabled";                   /* in zephyr/dts/arm/st/h7/stm32h7.dtsi:1187 */
		};

		/* node '/soc/sai1@40015804' defined in zephyr/dts/arm/st/h7/stm32h7.dtsi:1190 */
		sai1_a: sai1@40015804 {
			compatible = "st,stm32-sai";           /* in zephyr/dts/arm/st/h7/stm32h7.dtsi:1191 */
			#address-cells = < 0x1 >;              /* in zephyr/dts/arm/st/h7/stm32h7.dtsi:1192 */
			#size-cells = < 0x0 >;                 /* in zephyr/dts/arm/st/h7/stm32h7.dtsi:1193 */
			reg = < 0x40015804 0x20 >;             /* in zephyr/dts/arm/st/h7/stm32h7.dtsi:1194 */
			clocks = < &rcc 0xf0 0x400000 >,
			         < &rcc 0xb 0x1400050 >;       /* in zephyr/dts/arm/st/h7/stm32h7.dtsi:1195 */
			dmas = < &dma1 0x2 0x57 0x22800 0x0 >; /* in zephyr/dts/arm/st/h7/stm32h7.dtsi:1197 */
			status = "disabled";                   /* in zephyr/dts/arm/st/h7/stm32h7.dtsi:1199 */
		};

		/* node '/soc/sai1@40015824' defined in zephyr/dts/arm/st/h7/stm32h7.dtsi:1202 */
		sai1_b: sai1@40015824 {
			compatible = "st,stm32-sai";           /* in zephyr/dts/arm/st/h7/stm32h7.dtsi:1203 */
			#address-cells = < 0x1 >;              /* in zephyr/dts/arm/st/h7/stm32h7.dtsi:1204 */
			#size-cells = < 0x0 >;                 /* in zephyr/dts/arm/st/h7/stm32h7.dtsi:1205 */
			reg = < 0x40015824 0x20 >;             /* in zephyr/dts/arm/st/h7/stm32h7.dtsi:1206 */
			clocks = < &rcc 0xf0 0x400000 >,
			         < &rcc 0xb 0x1400050 >;       /* in zephyr/dts/arm/st/h7/stm32h7.dtsi:1207 */
			dmas = < &dma1 0x3 0x58 0x22800 0x0 >; /* in zephyr/dts/arm/st/h7/stm32h7.dtsi:1209 */
			status = "disabled";                   /* in zephyr/dts/arm/st/h7/stm32h7.dtsi:1211 */
		};

		/* node '/soc/comparator@5800380c' defined in zephyr/dts/arm/st/h7/stm32h7.dtsi:1214 */
		comp1_ch1: comparator@5800380c {
			compatible = "st,stm32h7-comp",
			             "st,stm32-comp";   /* in zephyr/dts/arm/st/h7/stm32h7.dtsi:1215 */
			reg = < 0x5800380c 0x200 >;     /* in zephyr/dts/arm/st/h7/stm32h7.dtsi:1216 */
			interrupts = < 0x89 0x0 >;      /* in zephyr/dts/arm/st/h7/stm32h7.dtsi:1217 */
			st,exti-line = < 0x14 >;        /* in zephyr/dts/arm/st/h7/stm32h7.dtsi:1218 */
			clocks = < &rcc 0xf4 0x4000 >;  /* in zephyr/dts/arm/st/h7/stm32h7.dtsi:1219 */
			status = "disabled";            /* in zephyr/dts/arm/st/h7/stm32h7.dtsi:1220 */
		};

		/* node '/soc/comparator@58003810' defined in zephyr/dts/arm/st/h7/stm32h7.dtsi:1223 */
		comp1_ch2: comparator@58003810 {
			compatible = "st,stm32h7-comp",
			             "st,stm32-comp";   /* in zephyr/dts/arm/st/h7/stm32h7.dtsi:1224 */
			reg = < 0x58003810 0x200 >;     /* in zephyr/dts/arm/st/h7/stm32h7.dtsi:1225 */
			interrupts = < 0x89 0x0 >;      /* in zephyr/dts/arm/st/h7/stm32h7.dtsi:1226 */
			st,exti-line = < 0x14 >;        /* in zephyr/dts/arm/st/h7/stm32h7.dtsi:1227 */
			clocks = < &rcc 0xf4 0x4000 >;  /* in zephyr/dts/arm/st/h7/stm32h7.dtsi:1228 */
			status = "disabled";            /* in zephyr/dts/arm/st/h7/stm32h7.dtsi:1229 */
		};

		/* node '/soc/serial@40011800' defined in zephyr/dts/arm/st/h7/stm32h723.dtsi:27 */
		uart9: serial@40011800 {
			compatible = "st,stm32-uart"; /* in zephyr/dts/arm/st/h7/stm32h723.dtsi:28 */
			reg = < 0x40011800 0x400 >;   /* in zephyr/dts/arm/st/h7/stm32h723.dtsi:29 */
			clocks = < &rcc 0xf0 0x40 >;  /* in zephyr/dts/arm/st/h7/stm32h723.dtsi:30 */
			resets = < &rctl 0x1306 >;    /* in zephyr/dts/arm/st/h7/stm32h723.dtsi:31 */
			interrupts = < 0x9b 0x0 >;    /* in zephyr/dts/arm/st/h7/stm32h723.dtsi:32 */
			status = "disabled";          /* in zephyr/dts/arm/st/h7/stm32h723.dtsi:33 */
		};

		/* node '/soc/serial@40011c00' defined in zephyr/dts/arm/st/h7/stm32h723.dtsi:36 */
		usart10: serial@40011c00 {
			compatible = "st,stm32-usart",
			             "st,stm32-uart";  /* in zephyr/dts/arm/st/h7/stm32h723.dtsi:37 */
			reg = < 0x40011c00 0x400 >;    /* in zephyr/dts/arm/st/h7/stm32h723.dtsi:38 */
			clocks = < &rcc 0xf0 0x80 >;   /* in zephyr/dts/arm/st/h7/stm32h723.dtsi:39 */
			resets = < &rctl 0x1307 >;     /* in zephyr/dts/arm/st/h7/stm32h723.dtsi:40 */
			interrupts = < 0x9c 0x0 >;     /* in zephyr/dts/arm/st/h7/stm32h723.dtsi:41 */
			status = "disabled";           /* in zephyr/dts/arm/st/h7/stm32h723.dtsi:42 */
		};

		/* node '/soc/usb@40040000' defined in zephyr/dts/arm/st/h7/stm32h723.dtsi:70 */
		usbotg_hs: zephyr_udc0: usb@40040000 {
			compatible = "st,stm32-otghs";                                                                                          /* in zephyr/dts/arm/st/h7/stm32h723.dtsi:71 */
			reg = < 0x40040000 0x40000 >;                                                                                           /* in zephyr/dts/arm/st/h7/stm32h723.dtsi:72 */
			interrupts = < 0x4d 0x0 >,
			             < 0x4a 0x0 >,
			             < 0x4b 0x0 >;                                                                                              /* in zephyr/dts/arm/st/h7/stm32h723.dtsi:73 */
			interrupt-names = "otghs",
			                  "ep1_out",
			                  "ep1_in";                                                                                             /* in zephyr/dts/arm/st/h7/stm32h723.dtsi:74 */
			num-bidir-endpoints = < 0x9 >;                                                                                          /* in zephyr/dts/arm/st/h7/stm32h723.dtsi:75 */
			ram-size = < 0x1000 >;                                                                                                  /* in zephyr/dts/arm/st/h7/stm32h723.dtsi:76 */
			pinctrl-0 = < &usb_otg_hs_ulpi_ck_pa5 &usb_otg_hs_ulpi_d0_pa3 &usb_otg_hs_ulpi_d1_pb0 &usb_otg_hs_ulpi_d2_pb1
			              &usb_otg_hs_ulpi_d3_pb10 &usb_otg_hs_ulpi_d4_pb11 &usb_otg_hs_ulpi_d5_pb12 &usb_otg_hs_ulpi_d6_pb13
			              &usb_otg_hs_ulpi_d7_pb5 &usb_otg_hs_ulpi_stp_pc0 &usb_otg_hs_ulpi_dir_pc2_c &usb_otg_hs_ulpi_nxt_pc3_c >; /* in workspace/hid-keyboard/boards/generic/keyboard_h723zg/keyboard_h723zg.dts:107 */
			pinctrl-names = "default";                                                                                              /* in workspace/hid-keyboard/boards/generic/keyboard_h723zg/keyboard_h723zg.dts:119 */
			maximum-speed = "high-speed";                                                                                           /* in workspace/hid-keyboard/boards/generic/keyboard_h723zg/keyboard_h723zg.dts:120 */
			clocks = < &rcc 0xd8 0x6000000 >,
			         < &rcc 0x5 0x3340054 >;                                                                                        /* in workspace/hid-keyboard/boards/generic/keyboard_h723zg/keyboard_h723zg.dts:122 */
			phys = < &otghs_ulpi_phy >;                                                                                             /* in workspace/hid-keyboard/boards/generic/keyboard_h723zg/keyboard_h723zg.dts:124 */
			status = "okay";                                                                                                        /* in workspace/hid-keyboard/boards/generic/keyboard_h723zg/keyboard_h723zg.dts:125 */
		};

		/* node '/soc/display-controller@50001000' defined in zephyr/dts/arm/st/h7/stm32h723.dtsi:84 */
		ltdc: display-controller@50001000 {
			compatible = "st,stm32-ltdc"; /* in zephyr/dts/arm/st/h7/stm32h723.dtsi:85 */
			reg = < 0x50001000 0x200 >;   /* in zephyr/dts/arm/st/h7/stm32h723.dtsi:86 */
			interrupts = < 0x58 0x0 >,
			             < 0x59 0x0 >;    /* in zephyr/dts/arm/st/h7/stm32h723.dtsi:87 */
			interrupt-names = "ltdc",
			                  "ltdc_er";  /* in zephyr/dts/arm/st/h7/stm32h723.dtsi:88 */
			clocks = < &rcc 0xe4 0x8 >;   /* in zephyr/dts/arm/st/h7/stm32h723.dtsi:89 */
			resets = < &rctl 0x1183 >;    /* in zephyr/dts/arm/st/h7/stm32h723.dtsi:90 */
			status = "disabled";          /* in zephyr/dts/arm/st/h7/stm32h723.dtsi:91 */
		};

		/* node '/soc/spi@5200a000' defined in zephyr/dts/arm/st/h7/stm32h723.dtsi:106 */
		octospi2: spi@5200a000 {
			compatible = "st,stm32-ospi";    /* in zephyr/dts/arm/st/h7/stm32h723.dtsi:107 */
			reg = < 0x5200a000 0x1000 >,
			      < 0x70000000 0x10000000 >; /* in zephyr/dts/arm/st/h7/stm32h723.dtsi:108 */
			interrupts = < 0x96 0x0 >;       /* in zephyr/dts/arm/st/h7/stm32h723.dtsi:109 */
			clock-names = "ospix",
			              "ospi-ker";        /* in zephyr/dts/arm/st/h7/stm32h723.dtsi:110 */
			clocks = < &rcc 0xd4 0x80000 >,
			         < &rcc 0x9 0x124004c >; /* in zephyr/dts/arm/st/h7/stm32h723.dtsi:111 */
			#address-cells = < 0x1 >;        /* in zephyr/dts/arm/st/h7/stm32h723.dtsi:113 */
			#size-cells = < 0x0 >;           /* in zephyr/dts/arm/st/h7/stm32h723.dtsi:114 */
			status = "disabled";             /* in zephyr/dts/arm/st/h7/stm32h723.dtsi:115 */
		};

		/* node '/soc/can@4000d400' defined in zephyr/dts/arm/st/h7/stm32h723.dtsi:118 */
		fdcan3: can@4000d400 {
			compatible = "st,stm32h7-fdcan";                         /* in zephyr/dts/arm/st/h7/stm32h723.dtsi:119 */
			reg = < 0x4000d400 0x400 >,
			      < 0x4000ac00 0x9f0 >;                              /* in zephyr/dts/arm/st/h7/stm32h723.dtsi:120 */
			reg-names = "m_can",
			            "message_ram";                               /* in zephyr/dts/arm/st/h7/stm32h723.dtsi:121 */
			clocks = < &rcc 0xec 0x100 >;                            /* in zephyr/dts/arm/st/h7/stm32h723.dtsi:122 */
			interrupts = < 0x9f 0x0 >,
			             < 0xa0 0x0 >,
			             < 0x3f 0x0 >;                               /* in zephyr/dts/arm/st/h7/stm32h723.dtsi:123 */
			interrupt-names = "int0",
			                  "int1",
			                  "calib";                               /* in zephyr/dts/arm/st/h7/stm32h723.dtsi:124 */
			bosch,mram-cfg = < 0x6a0 0x1c 0x8 0x3 0x3 0x0 0x3 0x3 >; /* in zephyr/dts/arm/st/h7/stm32h723.dtsi:125 */
			status = "disabled";                                     /* in zephyr/dts/arm/st/h7/stm32h723.dtsi:126 */
		};

		/* node '/soc/timers@4000e000' defined in zephyr/dts/arm/st/h7/stm32h723.dtsi:137 */
		timers23: timers@4000e000 {
			compatible = "st,stm32-timers";   /* in zephyr/dts/arm/st/h7/stm32h723.dtsi:138 */
			reg = < 0x4000e000 0x400 >;       /* in zephyr/dts/arm/st/h7/stm32h723.dtsi:139 */
			clocks = < &rcc 0xec 0x1000000 >,
			         < &rcc 0x12 0xff >;      /* in zephyr/dts/arm/st/h7/stm32h723.dtsi:140 */
			resets = < &rctl 0x1298 >;        /* in zephyr/dts/arm/st/h7/stm32h723.dtsi:142 */
			interrupts = < 0xa1 0x0 >;        /* in zephyr/dts/arm/st/h7/stm32h723.dtsi:143 */
			interrupt-names = "global";       /* in zephyr/dts/arm/st/h7/stm32h723.dtsi:144 */
			st,prescaler = < 0x0 >;           /* in zephyr/dts/arm/st/h7/stm32h723.dtsi:145 */
			status = "disabled";              /* in zephyr/dts/arm/st/h7/stm32h723.dtsi:146 */

			/* node '/soc/timers@4000e000/pwm' defined in zephyr/dts/arm/st/h7/stm32h723.dtsi:148 */
			pwm {
				compatible = "st,stm32-pwm"; /* in zephyr/dts/arm/st/h7/stm32h723.dtsi:149 */
				status = "disabled";         /* in zephyr/dts/arm/st/h7/stm32h723.dtsi:150 */
				#pwm-cells = < 0x3 >;        /* in zephyr/dts/arm/st/h7/stm32h723.dtsi:151 */
			};

			/* node '/soc/timers@4000e000/counter' defined in zephyr/dts/arm/st/h7/stm32h723.dtsi:154 */
			counter {
				compatible = "st,stm32-counter"; /* in zephyr/dts/arm/st/h7/stm32h723.dtsi:155 */
				status = "disabled";             /* in zephyr/dts/arm/st/h7/stm32h723.dtsi:156 */
			};

			/* node '/soc/timers@4000e000/qdec' defined in zephyr/dts/arm/st/h7/stm32h723.dtsi:159 */
			qdec {
				compatible = "st,stm32-qdec";    /* in zephyr/dts/arm/st/h7/stm32h723.dtsi:160 */
				st,input-filter-level = < 0x0 >; /* in zephyr/dts/arm/st/h7/stm32h723.dtsi:161 */
				status = "disabled";             /* in zephyr/dts/arm/st/h7/stm32h723.dtsi:162 */
			};
		};

		/* node '/soc/timers@4000e400' defined in zephyr/dts/arm/st/h7/stm32h723.dtsi:166 */
		timers24: timers@4000e400 {
			compatible = "st,stm32-timers";   /* in zephyr/dts/arm/st/h7/stm32h723.dtsi:167 */
			reg = < 0x4000e400 0x400 >;       /* in zephyr/dts/arm/st/h7/stm32h723.dtsi:168 */
			clocks = < &rcc 0xec 0x2000000 >,
			         < &rcc 0x12 0xff >;      /* in zephyr/dts/arm/st/h7/stm32h723.dtsi:169 */
			resets = < &rctl 0x1299 >;        /* in zephyr/dts/arm/st/h7/stm32h723.dtsi:171 */
			interrupts = < 0xa2 0x0 >;        /* in zephyr/dts/arm/st/h7/stm32h723.dtsi:172 */
			interrupt-names = "global";       /* in zephyr/dts/arm/st/h7/stm32h723.dtsi:173 */
			st,prescaler = < 0x0 >;           /* in zephyr/dts/arm/st/h7/stm32h723.dtsi:174 */
			status = "disabled";              /* in zephyr/dts/arm/st/h7/stm32h723.dtsi:175 */

			/* node '/soc/timers@4000e400/pwm' defined in zephyr/dts/arm/st/h7/stm32h723.dtsi:177 */
			pwm {
				compatible = "st,stm32-pwm"; /* in zephyr/dts/arm/st/h7/stm32h723.dtsi:178 */
				status = "disabled";         /* in zephyr/dts/arm/st/h7/stm32h723.dtsi:179 */
				#pwm-cells = < 0x3 >;        /* in zephyr/dts/arm/st/h7/stm32h723.dtsi:180 */
			};

			/* node '/soc/timers@4000e400/counter' defined in zephyr/dts/arm/st/h7/stm32h723.dtsi:183 */
			counter {
				compatible = "st,stm32-counter"; /* in zephyr/dts/arm/st/h7/stm32h723.dtsi:184 */
				status = "disabled";             /* in zephyr/dts/arm/st/h7/stm32h723.dtsi:185 */
			};

			/* node '/soc/timers@4000e400/qdec' defined in zephyr/dts/arm/st/h7/stm32h723.dtsi:188 */
			qdec {
				compatible = "st,stm32-qdec";    /* in zephyr/dts/arm/st/h7/stm32h723.dtsi:189 */
				st,input-filter-level = < 0x0 >; /* in zephyr/dts/arm/st/h7/stm32h723.dtsi:190 */
				status = "disabled";             /* in zephyr/dts/arm/st/h7/stm32h723.dtsi:191 */
			};
		};

		/* node '/soc/digi_dietemp@58006800' defined in zephyr/dts/arm/st/h7/stm32h723.dtsi:195 */
		digi_die_temp: digi_dietemp@58006800 {
			compatible = "st,stm32-digi-temp"; /* in zephyr/dts/arm/st/h7/stm32h723.dtsi:196 */
			reg = < 0x58006800 0x400 >;        /* in zephyr/dts/arm/st/h7/stm32h723.dtsi:197 */
			interrupts = < 0x93 0x0 >;         /* in zephyr/dts/arm/st/h7/stm32h723.dtsi:198 */
			interrupt-names = "digi_temp";     /* in zephyr/dts/arm/st/h7/stm32h723.dtsi:199 */
			clocks = < &rcc 0xf4 0x4000000 >;  /* in zephyr/dts/arm/st/h7/stm32h723.dtsi:200 */
			status = "disabled";               /* in zephyr/dts/arm/st/h7/stm32h723.dtsi:201 */
		};
	};

	/* node '/cpus' defined in zephyr/dts/arm/st/h7/stm32h7.dtsi:33 */
	cpus {
		#address-cells = < 0x1 >; /* in zephyr/dts/arm/st/h7/stm32h7.dtsi:34 */
		#size-cells = < 0x0 >;    /* in zephyr/dts/arm/st/h7/stm32h7.dtsi:35 */

		/* node '/cpus/cpu@0' defined in zephyr/dts/arm/st/h7/stm32h7.dtsi:37 */
		cpu0: cpu@0 {
			device_type = "cpu";          /* in zephyr/dts/arm/st/h7/stm32h7.dtsi:38 */
			compatible = "arm,cortex-m7"; /* in zephyr/dts/arm/st/h7/stm32h7.dtsi:39 */
			reg = < 0x0 >;                /* in zephyr/dts/arm/st/h7/stm32h7.dtsi:40 */
			#address-cells = < 0x1 >;     /* in zephyr/dts/arm/st/h7/stm32h7.dtsi:41 */
			#size-cells = < 0x1 >;        /* in zephyr/dts/arm/st/h7/stm32h7.dtsi:42 */

			/* node '/cpus/cpu@0/mpu@e000ed90' defined in zephyr/dts/arm/st/h7/stm32h7.dtsi:44 */
			mpu: mpu@e000ed90 {
				compatible = "arm,armv7m-mpu"; /* in zephyr/dts/arm/st/h7/stm32h7.dtsi:45 */
				reg = < 0xe000ed90 0x40 >;     /* in zephyr/dts/arm/st/h7/stm32h7.dtsi:46 */
			};
		};
	};

	/* node '/memory@0' defined in zephyr/dts/arm/st/h7/stm32h7.dtsi:51 */
	itcm: memory@0 {
		compatible = "zephyr,memory-region",
		             "arm,itcm";             /* in zephyr/dts/arm/st/h7/stm32h7.dtsi:52 */
		reg = < 0x0 0x10000 >;               /* in zephyr/dts/arm/st/h7/stm32h7.dtsi:53 */
		zephyr,memory-region = "ITCM";       /* in zephyr/dts/arm/st/h7/stm32h7.dtsi:54 */
	};

	/* node '/memory@20000000' defined in zephyr/dts/arm/st/h7/stm32h7.dtsi:57 */
	dtcm: memory@20000000 {
		compatible = "zephyr,memory-region",
		             "arm,dtcm";             /* in zephyr/dts/arm/st/h7/stm32h7.dtsi:58 */
		reg = < 0x20000000 0x20000 >;        /* in zephyr/dts/arm/st/h7/stm32h7.dtsi:59 */
		zephyr,memory-region = "DTCM";       /* in zephyr/dts/arm/st/h7/stm32h7.dtsi:60 */
	};

	/* node '/memory@90000000' defined in zephyr/dts/arm/st/h7/stm32h7.dtsi:63 */
	ext_memory: memory@90000000 {
		compatible = "zephyr,memory-region"; /* in zephyr/dts/arm/st/h7/stm32h7.dtsi:64 */
		reg = < 0x90000000 0x10000000 >;     /* in zephyr/dts/arm/st/h7/stm32h7.dtsi:65 */
		zephyr,memory-region = "EXTMEM";     /* in zephyr/dts/arm/st/h7/stm32h7.dtsi:66 */
		zephyr,memory-attr = < 0x2000000 >;  /* in zephyr/dts/arm/st/h7/stm32h7.dtsi:67 */
	};

	/* node '/clocks' defined in zephyr/dts/arm/st/h7/stm32h7.dtsi:70 */
	clocks {
		#address-cells = < 0x1 >; /* in zephyr/dts/arm/st/h7/stm32h7.dtsi:71 */
		#size-cells = < 0x0 >;    /* in zephyr/dts/arm/st/h7/stm32h7.dtsi:72 */

		/* node '/clocks/clk-hse' defined in zephyr/dts/arm/st/h7/stm32h7.dtsi:74 */
		clk_hse: clk-hse {
			#clock-cells = < 0x0 >;            /* in zephyr/dts/arm/st/h7/stm32h7.dtsi:75 */
			compatible = "st,stm32-hse-clock"; /* in zephyr/dts/arm/st/h7/stm32h7.dtsi:76 */
			clock-frequency = < 0x17d7840 >;   /* in workspace/hid-keyboard/boards/generic/keyboard_h723zg/keyboard_h723zg.dts:47 */
			status = "okay";                   /* in workspace/hid-keyboard/boards/generic/keyboard_h723zg/keyboard_h723zg.dts:48 */
			phandle = < 0x1a >;                /* in workspace/hid-keyboard/boards/generic/keyboard_h723zg/keyboard_h723zg.dts:61 */
		};

		/* node '/clocks/clk-hsi' defined in zephyr/dts/arm/st/h7/stm32h7.dtsi:80 */
		clk_hsi: clk-hsi {
			#clock-cells = < 0x0 >;              /* in zephyr/dts/arm/st/h7/stm32h7.dtsi:81 */
			compatible = "st,stm32h7-hsi-clock"; /* in zephyr/dts/arm/st/h7/stm32h7.dtsi:82 */
			hsi-div = < 0x1 >;                   /* in zephyr/dts/arm/st/h7/stm32h7.dtsi:83 */
			clock-frequency = < 0x3d09000 >;     /* in zephyr/dts/arm/st/h7/stm32h7.dtsi:84 */
			status = "disabled";                 /* in zephyr/dts/arm/st/h7/stm32h7.dtsi:85 */
		};

		/* node '/clocks/clk-hsi48' defined in zephyr/dts/arm/st/h7/stm32h7.dtsi:88 */
		clk_hsi48: clk-hsi48 {
			#clock-cells = < 0x0 >;          /* in zephyr/dts/arm/st/h7/stm32h7.dtsi:89 */
			compatible = "fixed-clock";      /* in zephyr/dts/arm/st/h7/stm32h7.dtsi:90 */
			clock-frequency = < 0x2dc6c00 >; /* in zephyr/dts/arm/st/h7/stm32h7.dtsi:91 */
			status = "okay";                 /* in workspace/hid-keyboard/boards/generic/keyboard_h723zg/keyboard_h723zg.dts:52 */
		};

		/* node '/clocks/clk-csi' defined in zephyr/dts/arm/st/h7/stm32h7.dtsi:95 */
		clk_csi: clk-csi {
			#clock-cells = < 0x0 >;         /* in zephyr/dts/arm/st/h7/stm32h7.dtsi:96 */
			compatible = "fixed-clock";     /* in zephyr/dts/arm/st/h7/stm32h7.dtsi:97 */
			clock-frequency = < 0x3d0900 >; /* in zephyr/dts/arm/st/h7/stm32h7.dtsi:98 */
			status = "disabled";            /* in zephyr/dts/arm/st/h7/stm32h7.dtsi:99 */
		};

		/* node '/clocks/clk-lse' defined in zephyr/dts/arm/st/h7/stm32h7.dtsi:102 */
		clk_lse: clk-lse {
			#clock-cells = < 0x0 >;            /* in zephyr/dts/arm/st/h7/stm32h7.dtsi:103 */
			compatible = "st,stm32-lse-clock"; /* in zephyr/dts/arm/st/h7/stm32h7.dtsi:104 */
			clock-frequency = < 0x8000 >;      /* in zephyr/dts/arm/st/h7/stm32h7.dtsi:105 */
			driving-capability = < 0x0 >;      /* in zephyr/dts/arm/st/h7/stm32h7.dtsi:106 */
			status = "disabled";               /* in zephyr/dts/arm/st/h7/stm32h7.dtsi:107 */
		};

		/* node '/clocks/clk-lsi' defined in zephyr/dts/arm/st/h7/stm32h7.dtsi:110 */
		clk_lsi: clk-lsi {
			#clock-cells = < 0x0 >;       /* in zephyr/dts/arm/st/h7/stm32h7.dtsi:111 */
			compatible = "fixed-clock";   /* in zephyr/dts/arm/st/h7/stm32h7.dtsi:112 */
			clock-frequency = < 0x7d00 >; /* in zephyr/dts/arm/st/h7/stm32h7.dtsi:113 */
			status = "okay";              /* in workspace/hid-keyboard/boards/generic/keyboard_h723zg/keyboard_h723zg.dts:43 */
		};

		/* node '/clocks/pll@0' defined in zephyr/dts/arm/st/h7/stm32h7.dtsi:117 */
		pll: pll@0 {
			#clock-cells = < 0x0 >;              /* in zephyr/dts/arm/st/h7/stm32h7.dtsi:118 */
			compatible = "st,stm32h7-pll-clock"; /* in zephyr/dts/arm/st/h7/stm32h7.dtsi:119 */
			reg = < 0x0 >;                       /* in zephyr/dts/arm/st/h7/stm32h7.dtsi:120 */
			div-m = < 0x5 >;                     /* in workspace/hid-keyboard/boards/generic/keyboard_h723zg/keyboard_h723zg.dts:56 */
			mul-n = < 0x6e >;                    /* in workspace/hid-keyboard/boards/generic/keyboard_h723zg/keyboard_h723zg.dts:57 */
			div-p = < 0x1 >;                     /* in workspace/hid-keyboard/boards/generic/keyboard_h723zg/keyboard_h723zg.dts:58 */
			div-q = < 0x5 >;                     /* in workspace/hid-keyboard/boards/generic/keyboard_h723zg/keyboard_h723zg.dts:59 */
			div-r = < 0x2 >;                     /* in workspace/hid-keyboard/boards/generic/keyboard_h723zg/keyboard_h723zg.dts:60 */
			clocks = < &clk_hse >;               /* in workspace/hid-keyboard/boards/generic/keyboard_h723zg/keyboard_h723zg.dts:61 */
			status = "okay";                     /* in workspace/hid-keyboard/boards/generic/keyboard_h723zg/keyboard_h723zg.dts:62 */
			phandle = < 0x2 >;                   /* in workspace/hid-keyboard/boards/generic/keyboard_h723zg/keyboard_h723zg.dts:66 */
		};

		/* node '/clocks/pll@1' defined in zephyr/dts/arm/st/h7/stm32h7.dtsi:124 */
		pll2: pll@1 {
			#clock-cells = < 0x0 >;              /* in zephyr/dts/arm/st/h7/stm32h7.dtsi:125 */
			compatible = "st,stm32h7-pll-clock"; /* in zephyr/dts/arm/st/h7/stm32h7.dtsi:126 */
			reg = < 0x1 >;                       /* in zephyr/dts/arm/st/h7/stm32h7.dtsi:127 */
			status = "disabled";                 /* in zephyr/dts/arm/st/h7/stm32h7.dtsi:128 */
		};

		/* node '/clocks/pll@2' defined in zephyr/dts/arm/st/h7/stm32h7.dtsi:131 */
		pll3: pll@2 {
			#clock-cells = < 0x0 >;              /* in zephyr/dts/arm/st/h7/stm32h7.dtsi:132 */
			compatible = "st,stm32h7-pll-clock"; /* in zephyr/dts/arm/st/h7/stm32h7.dtsi:133 */
			reg = < 0x2 >;                       /* in zephyr/dts/arm/st/h7/stm32h7.dtsi:134 */
			status = "disabled";                 /* in zephyr/dts/arm/st/h7/stm32h7.dtsi:135 */
		};

		/* node '/clocks/perck' defined in zephyr/dts/arm/st/h7/stm32h7.dtsi:138 */
		perck: perck {
			#clock-cells = < 0x0 >;            /* in zephyr/dts/arm/st/h7/stm32h7.dtsi:139 */
			compatible = "st,stm32-clock-mux"; /* in zephyr/dts/arm/st/h7/stm32h7.dtsi:140 */
			status = "disabled";               /* in zephyr/dts/arm/st/h7/stm32h7.dtsi:141 */
		};
	};

	/* node '/mcos' defined in zephyr/dts/arm/st/h7/stm32h7.dtsi:145 */
	mcos {

		/* node '/mcos/mco1' defined in zephyr/dts/arm/st/h7/stm32h7.dtsi:146 */
		mco1: mco1 {
			compatible = "st,stm32-clock-mco"; /* in zephyr/dts/arm/st/h7/stm32h7.dtsi:147 */
			status = "disabled";               /* in zephyr/dts/arm/st/h7/stm32h7.dtsi:148 */
		};

		/* node '/mcos/mco2' defined in zephyr/dts/arm/st/h7/stm32h7.dtsi:151 */
		mco2: mco2 {
			compatible = "st,stm32-clock-mco"; /* in zephyr/dts/arm/st/h7/stm32h7.dtsi:152 */
			status = "disabled";               /* in zephyr/dts/arm/st/h7/stm32h7.dtsi:153 */
		};
	};

	/* node '/dietemp' defined in zephyr/dts/arm/st/h7/stm32h7.dtsi:1233 */
	die_temp: dietemp {
		compatible = "st,stm32-temp-cal"; /* in zephyr/dts/arm/st/h7/stm32h7.dtsi:1234 */
		ts-cal1-addr = < 0x1ff1e820 >;    /* in zephyr/dts/arm/st/h7/stm32h7.dtsi:1235 */
		ts-cal2-addr = < 0x1ff1e840 >;    /* in zephyr/dts/arm/st/h7/stm32h7.dtsi:1236 */
		ts-cal1-temp = < 0x1e >;          /* in zephyr/dts/arm/st/h7/stm32h7.dtsi:1237 */
		ts-cal-vrefanalog = < 0xce4 >;    /* in zephyr/dts/arm/st/h7/stm32h7.dtsi:1239 */
		ts-cal-resolution = < 0x10 >;     /* in zephyr/dts/arm/st/h7/stm32h7.dtsi:1240 */
		status = "disabled";              /* in zephyr/dts/arm/st/h7/stm32h7.dtsi:1242 */
		io-channels = < &adc3 0x11 >;     /* in zephyr/dts/arm/st/h7/stm32h723.dtsi:240 */
		ts-cal2-temp = < 0x82 >;          /* in zephyr/dts/arm/st/h7/stm32h723.dtsi:241 */
	};

	/* node '/vbat' defined in zephyr/dts/arm/st/h7/stm32h7.dtsi:1245 */
	vbat: vbat {
		compatible = "st,stm32-vbat"; /* in zephyr/dts/arm/st/h7/stm32h7.dtsi:1246 */
		ratio = < 0x4 >;              /* in zephyr/dts/arm/st/h7/stm32h7.dtsi:1247 */
		status = "disabled";          /* in zephyr/dts/arm/st/h7/stm32h7.dtsi:1248 */
		io-channels = < &adc3 0x10 >; /* in zephyr/dts/arm/st/h7/stm32h723.dtsi:249 */
	};

	/* node '/vref' defined in zephyr/dts/arm/st/h7/stm32h7.dtsi:1251 */
	vref: vref {
		compatible = "st,stm32-vref";      /* in zephyr/dts/arm/st/h7/stm32h7.dtsi:1252 */
		vrefint-cal-addr = < 0x1ff1e860 >; /* in zephyr/dts/arm/st/h7/stm32h7.dtsi:1253 */
		vrefint-cal-mv = < 0xce4 >;        /* in zephyr/dts/arm/st/h7/stm32h7.dtsi:1254 */
		vrefint-cal-resolution = < 0x10 >; /* in zephyr/dts/arm/st/h7/stm32h7.dtsi:1255 */
		status = "disabled";               /* in zephyr/dts/arm/st/h7/stm32h7.dtsi:1256 */
		io-channels = < &adc3 0x12 >;      /* in zephyr/dts/arm/st/h7/stm32h723.dtsi:245 */
	};

	/* node '/smbus1' defined in zephyr/dts/arm/st/h7/stm32h7.dtsi:1259 */
	smbus1: smbus1 {
		compatible = "st,stm32-smbus"; /* in zephyr/dts/arm/st/h7/stm32h7.dtsi:1260 */
		#address-cells = < 0x1 >;      /* in zephyr/dts/arm/st/h7/stm32h7.dtsi:1261 */
		#size-cells = < 0x0 >;         /* in zephyr/dts/arm/st/h7/stm32h7.dtsi:1262 */
		i2c = < &i2c1 >;               /* in zephyr/dts/arm/st/h7/stm32h7.dtsi:1263 */
		status = "disabled";           /* in zephyr/dts/arm/st/h7/stm32h7.dtsi:1264 */
	};

	/* node '/smbus2' defined in zephyr/dts/arm/st/h7/stm32h7.dtsi:1267 */
	smbus2: smbus2 {
		compatible = "st,stm32-smbus"; /* in zephyr/dts/arm/st/h7/stm32h7.dtsi:1268 */
		#address-cells = < 0x1 >;      /* in zephyr/dts/arm/st/h7/stm32h7.dtsi:1269 */
		#size-cells = < 0x0 >;         /* in zephyr/dts/arm/st/h7/stm32h7.dtsi:1270 */
		i2c = < &i2c2 >;               /* in zephyr/dts/arm/st/h7/stm32h7.dtsi:1271 */
		status = "disabled";           /* in zephyr/dts/arm/st/h7/stm32h7.dtsi:1272 */
	};

	/* node '/smbus3' defined in zephyr/dts/arm/st/h7/stm32h7.dtsi:1275 */
	smbus3: smbus3 {
		compatible = "st,stm32-smbus"; /* in zephyr/dts/arm/st/h7/stm32h7.dtsi:1276 */
		#address-cells = < 0x1 >;      /* in zephyr/dts/arm/st/h7/stm32h7.dtsi:1277 */
		#size-cells = < 0x0 >;         /* in zephyr/dts/arm/st/h7/stm32h7.dtsi:1278 */
		i2c = < &i2c3 >;               /* in zephyr/dts/arm/st/h7/stm32h7.dtsi:1279 */
		status = "disabled";           /* in zephyr/dts/arm/st/h7/stm32h7.dtsi:1280 */
	};

	/* node '/smbus4' defined in zephyr/dts/arm/st/h7/stm32h7.dtsi:1283 */
	smbus4: smbus4 {
		compatible = "st,stm32-smbus"; /* in zephyr/dts/arm/st/h7/stm32h7.dtsi:1284 */
		#address-cells = < 0x1 >;      /* in zephyr/dts/arm/st/h7/stm32h7.dtsi:1285 */
		#size-cells = < 0x0 >;         /* in zephyr/dts/arm/st/h7/stm32h7.dtsi:1286 */
		i2c = < &i2c4 >;               /* in zephyr/dts/arm/st/h7/stm32h7.dtsi:1287 */
		status = "disabled";           /* in zephyr/dts/arm/st/h7/stm32h7.dtsi:1288 */
	};

	/* node '/memory@24000000' defined in zephyr/dts/arm/st/h7/stm32h723.dtsi:206 */
	sram0: memory@24000000 {
		reg = < 0x24000000 0x50000 >;        /* in zephyr/dts/arm/st/h7/stm32h723.dtsi:207 */
		compatible = "zephyr,memory-region",
		             "mmio-sram";            /* in zephyr/dts/arm/st/h7/stm32h723.dtsi:208 */
		zephyr,memory-region = "SRAM0";      /* in zephyr/dts/arm/st/h7/stm32h723.dtsi:209 */
	};

	/* node '/memory@30000000' defined in zephyr/dts/arm/st/h7/stm32h723.dtsi:213 */
	sram1: memory@30000000 {
		reg = < 0x30000000 0x4000 >;         /* in zephyr/dts/arm/st/h7/stm32h723.dtsi:214 */
		compatible = "zephyr,memory-region",
		             "mmio-sram";            /* in zephyr/dts/arm/st/h7/stm32h723.dtsi:215 */
		zephyr,memory-region = "SRAM1";      /* in zephyr/dts/arm/st/h7/stm32h723.dtsi:216 */
	};

	/* node '/memory@30004000' defined in zephyr/dts/arm/st/h7/stm32h723.dtsi:220 */
	sram2: memory@30004000 {
		reg = < 0x30004000 0x4000 >;         /* in zephyr/dts/arm/st/h7/stm32h723.dtsi:221 */
		compatible = "zephyr,memory-region",
		             "mmio-sram";            /* in zephyr/dts/arm/st/h7/stm32h723.dtsi:222 */
		zephyr,memory-region = "SRAM2";      /* in zephyr/dts/arm/st/h7/stm32h723.dtsi:223 */
		#memory-region-cells = < 0x0 >;      /* in zephyr/dts/arm/st/h7/stm32h723.dtsi:224 */
		phandle = < 0xb >;                   /* in zephyr/dts/arm/st/h7/stm32h7.dtsi:1134 */
	};

	/* node '/memory@38000000' defined in zephyr/dts/arm/st/h7/stm32h723.dtsi:228 */
	sram4: memory@38000000 {
		reg = < 0x38000000 0x4000 >;         /* in zephyr/dts/arm/st/h7/stm32h723.dtsi:229 */
		compatible = "zephyr,memory-region",
		             "mmio-sram";            /* in zephyr/dts/arm/st/h7/stm32h723.dtsi:230 */
		zephyr,memory-region = "SRAM4";      /* in zephyr/dts/arm/st/h7/stm32h723.dtsi:231 */
	};

	/* node '/otghs_fs_phy' defined in zephyr/dts/arm/st/h7/stm32h723.dtsi:234 */
	otghs_fs_phy: otghs_fs_phy {
		compatible = "usb-nop-xceiv"; /* in zephyr/dts/arm/st/h7/stm32h723.dtsi:235 */
		#phy-cells = < 0x0 >;         /* in zephyr/dts/arm/st/h7/stm32h723.dtsi:236 */
	};

	/* node '/leds' defined in workspace/hid-keyboard/boards/generic/keyboard_h723zg/keyboard_h723zg.dts:23 */
	leds: leds {
		compatible = "gpio-leds"; /* in workspace/hid-keyboard/boards/generic/keyboard_h723zg/keyboard_h723zg.dts:24 */

		/* node '/leds/led_0' defined in workspace/hid-keyboard/boards/generic/keyboard_h723zg/keyboard_h723zg.dts:26 */
		orange_led: led_0 {
			gpios = < &gpiod 0x7 0x0 >; /* in workspace/hid-keyboard/boards/generic/keyboard_h723zg/keyboard_h723zg.dts:27 */
			label = "Caps Led";         /* in workspace/hid-keyboard/boards/generic/keyboard_h723zg/keyboard_h723zg.dts:28 */
		};
	};

	/* node '/otghs_ulpis_phy' defined in workspace/hid-keyboard/boards/generic/keyboard_h723zg/keyboard_h723zg.dts:32 */
	otghs_ulpi_phy: otghs_ulpis_phy {
		compatible = "usb-ulpi-phy"; /* in workspace/hid-keyboard/boards/generic/keyboard_h723zg/keyboard_h723zg.dts:33 */
		#phy-cells = < 0x0 >;        /* in workspace/hid-keyboard/boards/generic/keyboard_h723zg/keyboard_h723zg.dts:34 */
		phandle = < 0x19 >;          /* in workspace/hid-keyboard/boards/generic/keyboard_h723zg/keyboard_h723zg.dts:124 */
	};

	/* node '/hid_dev_0' defined in workspace/hid-keyboard/app.overlay:8 */
	hid_dev_0: hid_dev_0 {
		compatible = "zephyr,hid-device"; /* in workspace/hid-keyboard/app.overlay:9 */
		label = "HID0";                   /* in workspace/hid-keyboard/app.overlay:10 */
		protocol-code = "keyboard";       /* in workspace/hid-keyboard/app.overlay:11 */
		in-report-size = < 0x40 >;        /* in workspace/hid-keyboard/app.overlay:12 */
		in-polling-period-us = < 0x3e8 >; /* in workspace/hid-keyboard/app.overlay:13 */
	};
};
